VERSION "5.2.0"

NS_ :

BS_:

BU_:

BO_ 2565341438 PGN_59392_isoAcknowledgement: 8 Vector__XXX
 SG_ pgn : 40|24@1+ (1,0) [0|0] "" Vector__XXX
 SG_ reserved : 16|24@1+ (1,0) [0|0] "" Vector__XXX
 SG_ groupFunction : 8|8@1+ (1,0) [0|0] "" Vector__XXX
 SG_ control : 0|8@1+ (1,0) [0|0] "" Vector__XXX

BO_ 2565472510 PGN_59904_isoRequest: 8 Vector__XXX
 SG_ pgn : 0|24@1+ (1,0) [0|0] "" Vector__XXX

BO_ 2565538046 PGN_60160_isoTransportProtocolDa: 8 Vector__XXX
 SG_ data : 8|56@1+ (1,0) [0|0] "" Vector__XXX
 SG_ sid : 0|8@1+ (1,0) [0|0] "" Vector__XXX

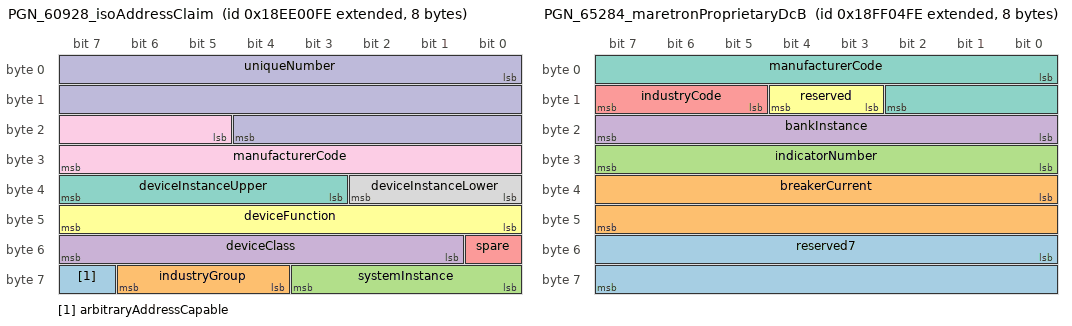
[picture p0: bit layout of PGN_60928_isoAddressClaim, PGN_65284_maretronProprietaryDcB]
BO_ 2565734654 PGN_60928_isoAddressClaim: 8 Vector__XXX
 SG_ arbitraryAddressCapable : 63|1@1+ (1,0) [0|0] "" Vector__XXX
 SG_ industryGroup : 60|3@1+ (1,0) [0|0] "" Vector__XXX
 SG_ systemInstance : 56|4@1+ (1,0) [0|0] "" Vector__XXX
 SG_ deviceClass : 49|7@1+ (1,0) [0|0] "" Vector__XXX
 SG_ spare : 48|1@1+ (1,0) [0|0] "" Vector__XXX
 SG_ deviceFunction : 40|8@1+ (1,0) [0|0] "" Vector__XXX
 SG_ deviceInstanceUpper : 35|5@1+ (1,0) [0|0] "" Vector__XXX
 SG_ deviceInstanceLower : 32|3@1+ (1,0) [0|0] "" Vector__XXX
 SG_ manufacturerCode : 21|11@1+ (1,0) [0|0] "" Vector__XXX
 SG_ uniqueNumber : 0|21@1+ (1,0) [0|0] "" Vector__XXX

BO_ 2566777342 PGN_65001_bus1PhaseCBasicAcQuant: 8 Vector__XXX
 SG_ reserved : 48|16@1+ (1,0) [0|0] "" Vector__XXX
 SG_ acFrequency : 32|16@1+ (0.0078125,0) [0|0] "Hz" Vector__XXX
 SG_ lineNeutralAcRmsVoltage : 16|16@1+ (1,0) [0|0] "V" Vector__XXX
 SG_ lineLineAcRmsVoltage : 0|16@1+ (1,0) [0|0] "V" Vector__XXX

BO_ 2566777598 PGN_65002_bus1PhaseBBasicAcQuant: 8 Vector__XXX
 SG_ reserved : 48|16@1+ (1,0) [0|0] "" Vector__XXX
 SG_ acFrequency : 32|16@1+ (0.0078125,0) [0|0] "Hz" Vector__XXX
 SG_ lineNeutralAcRmsVoltage : 16|16@1+ (1,0) [0|0] "V" Vector__XXX
 SG_ lineLineAcRmsVoltage : 0|16@1+ (1,0) [0|0] "V" Vector__XXX

BO_ 2566777854 PGN_65003_bus1PhaseABasicAcQuant: 8 Vector__XXX
 SG_ reserved : 48|16@1+ (1,0) [0|0] "" Vector__XXX
 SG_ acFrequency : 32|16@1+ (0.0078125,0) [0|0] "Hz" Vector__XXX
 SG_ lineNeutralAcRmsVoltage : 16|16@1+ (1,0) [0|0] "V" Vector__XXX
 SG_ lineLineAcRmsVoltage : 0|16@1+ (1,0) [0|0] "V" Vector__XXX

BO_ 2566778110 PGN_65004_bus1AverageBasicAcQuan: 8 Vector__XXX
 SG_ reserved : 48|16@1+ (1,0) [0|0] "" Vector__XXX
 SG_ acFrequency : 32|16@1+ (0.0078125,0) [0|0] "Hz" Vector__XXX
 SG_ lineNeutralAcRmsVoltage : 16|16@1+ (1,0) [0|0] "V" Vector__XXX
 SG_ lineLineAcRmsVoltage : 0|16@1+ (1,0) [0|0] "V" Vector__XXX

BO_ 2566778366 PGN_65005_utilityTotalAcEnergy: 8 Vector__XXX
 SG_ totalEnergyImport : 32|32@1+ (1,0) [0|0] "kWh" Vector__XXX
 SG_ totalEnergyExport : 0|32@1+ (1,0) [0|0] "kWh" Vector__XXX

BO_ 2566778622 PGN_65006_utilityPhaseCAcReactiv: 8 Vector__XXX
 SG_ reserved : 34|30@1+ (1,0) [0|0] "" Vector__XXX
 SG_ powerFactorLagging : 32|2@1+ (1,0) [0|0] "" Vector__XXX
 SG_ powerFactor : 16|16@1+ (6.10352e-05,0) [0|0] "Cos Phi" Vector__XXX
 SG_ reactivePower : 0|16@1+ (1,0) [0|0] "VAR" Vector__XXX

BO_ 2566778878 PGN_65007_utilityPhaseCAcPower: 8 Vector__XXX
 SG_ apparentPower : 32|32@1- (1,0) [0|0] "VA" Vector__XXX
 SG_ realPower : 0|32@1- (1,0) [0|0] "W" Vector__XXX

BO_ 2566779134 PGN_65008_utilityPhaseCBasicAcQu: 8 Vector__XXX
 SG_ acRmsCurrent : 48|16@1+ (1,0) [0|0] "A" Vector__XXX
 SG_ acFrequency : 32|16@1+ (0.0078125,0) [0|0] "Hz" Vector__XXX
 SG_ lineNeutralAcRmsVoltage : 16|16@1+ (1,0) [0|0] "V" Vector__XXX
 SG_ lineLineAcRmsVoltage : 0|16@1+ (1,0) [0|0] "V" Vector__XXX

BO_ 2566779390 PGN_65009_utilityPhaseBAcReactiv: 8 Vector__XXX
 SG_ reserved : 34|30@1+ (1,0) [0|0] "" Vector__XXX
 SG_ powerFactorLagging : 32|2@1+ (1,0) [0|0] "" Vector__XXX
 SG_ powerFactor : 16|16@1+ (6.10352e-05,0) [0|0] "Cos Phi" Vector__XXX
 SG_ reactivePower : 0|16@1+ (1,0) [0|0] "VAR" Vector__XXX

BO_ 2566779646 PGN_65010_utilityPhaseBAcPower: 8 Vector__XXX
 SG_ apparentPower : 32|32@1- (1,0) [0|0] "VA" Vector__XXX
 SG_ realPower : 0|32@1- (1,0) [0|0] "W" Vector__XXX

BO_ 2566779902 PGN_65011_utilityPhaseBBasicAcQu: 8 Vector__XXX
 SG_ acRmsCurrent : 48|16@1+ (1,0) [0|0] "A" Vector__XXX
 SG_ acFrequency : 32|16@1+ (0.0078125,0) [0|0] "Hz" Vector__XXX
 SG_ lineNeutralAcRmsVoltage : 16|16@1+ (1,0) [0|0] "V" Vector__XXX
 SG_ lineLineAcRmsVoltage : 0|16@1+ (1,0) [0|0] "V" Vector__XXX

BO_ 2566780158 PGN_65012_utilityPhaseAAcReactiv: 8 Vector__XXX
 SG_ reserved : 50|14@1+ (1,0) [0|0] "" Vector__XXX
 SG_ powerFactorLagging : 48|2@1+ (1,0) [0|0] "" Vector__XXX
 SG_ powerFactor : 32|16@1+ (6.10352e-05,0) [0|0] "Cos Phi" Vector__XXX
 SG_ reactivePower : 0|32@1- (1,0) [0|0] "VAR" Vector__XXX

BO_ 2566780414 PGN_65013_utilityPhaseAAcPower: 8 Vector__XXX
 SG_ apparentPower : 32|32@1- (1,0) [0|0] "VA" Vector__XXX
 SG_ realPower : 0|32@1- (1,0) [0|0] "W" Vector__XXX

BO_ 2566780670 PGN_65014_utilityPhaseABasicAcQu: 8 Vector__XXX
 SG_ acRmsCurrent : 48|16@1+ (1,0) [0|0] "A" Vector__XXX
 SG_ acFrequency : 32|16@1+ (0.0078125,0) [0|0] "Hz" Vector__XXX
 SG_ lineNeutralAcRmsVoltage : 16|16@1+ (1,0) [0|0] "V" Vector__XXX
 SG_ lineLineAcRmsVoltage : 0|16@1+ (1,0) [0|0] "V" Vector__XXX

BO_ 2566780926 PGN_65015_utilityTotalAcReactive: 8 Vector__XXX
 SG_ reserved : 50|14@1+ (1,0) [0|0] "" Vector__XXX
 SG_ powerFactorLagging : 48|2@1+ (1,0) [0|0] "" Vector__XXX
 SG_ powerFactor : 32|16@1+ (6.10352e-05,0) [0|0] "Cos Phi" Vector__XXX
 SG_ reactivePower : 0|32@1- (1,0) [0|0] "VAR" Vector__XXX

BO_ 2566781182 PGN_65016_utilityTotalAcPower: 8 Vector__XXX
 SG_ apparentPower : 32|32@1- (1,0) [0|0] "VA" Vector__XXX
 SG_ realPower : 0|32@1- (1,0) [0|0] "W" Vector__XXX

BO_ 2566781438 PGN_65017_utilityAverageBasicAcQ: 8 Vector__XXX
 SG_ acRmsCurrent : 48|16@1+ (1,0) [0|0] "A" Vector__XXX
 SG_ acFrequency : 32|16@1+ (0.0078125,0) [0|0] "Hz" Vector__XXX
 SG_ lineNeutralAcRmsVoltage : 16|16@1+ (1,0) [0|0] "V" Vector__XXX
 SG_ lineLineAcRmsVoltage : 0|16@1+ (1,0) [0|0] "V" Vector__XXX

BO_ 2566781694 PGN_65018_generatorTotalAcEnergy: 8 Vector__XXX
 SG_ totalEnergyImport : 32|32@1+ (1,0) [0|0] "kWh" Vector__XXX
 SG_ totalEnergyExport : 0|32@1+ (1,0) [0|0] "kWh" Vector__XXX

BO_ 2566781950 PGN_65019_generatorPhaseCAcReact: 8 Vector__XXX
 SG_ reserved : 50|14@1+ (1,0) [0|0] "" Vector__XXX
 SG_ powerFactorLagging : 48|2@1+ (1,0) [0|0] "" Vector__XXX
 SG_ powerFactor : 32|16@1+ (6.10352e-05,0) [0|0] "Cos Phi" Vector__XXX
 SG_ reactivePower : 0|32@1- (1,0) [0|0] "VAR" Vector__XXX

BO_ 2566782206 PGN_65020_generatorPhaseCAcPower: 8 Vector__XXX
 SG_ apparentPower : 32|32@1- (1,0) [0|0] "VAR" Vector__XXX
 SG_ realPower : 0|32@1- (1,0) [0|0] "W" Vector__XXX

BO_ 2566782462 PGN_65021_generatorPhaseCBasicAc: 8 Vector__XXX
 SG_ acRmsCurrent : 48|16@1+ (1,0) [0|0] "A" Vector__XXX
 SG_ acFrequency : 32|16@1+ (0.0078125,0) [0|0] "Hz" Vector__XXX
 SG_ lineNeutralAcRmsVoltage : 16|16@1+ (1,0) [0|0] "V" Vector__XXX
 SG_ lineLineAcRmsVoltage : 0|16@1+ (1,0) [0|0] "V" Vector__XXX

BO_ 2566782718 PGN_65022_generatorPhaseBAcReact: 8 Vector__XXX
 SG_ reserved : 50|14@1+ (1,0) [0|0] "" Vector__XXX
 SG_ powerFactorLagging : 48|2@1+ (1,0) [0|0] "" Vector__XXX
 SG_ powerFactor : 32|16@1+ (6.10352e-05,0) [0|0] "Cos Phi" Vector__XXX
 SG_ reactivePower : 0|32@1- (1,0) [0|0] "VAR" Vector__XXX

BO_ 2566782974 PGN_65023_generatorPhaseBAcPower: 8 Vector__XXX
 SG_ apparentPower : 32|32@1- (1,0) [0|0] "VA" Vector__XXX
 SG_ realPower : 0|32@1- (1,0) [0|0] "W" Vector__XXX

BO_ 2566783230 PGN_65024_generatorPhaseBBasicAc: 8 Vector__XXX
 SG_ acRmsCurrent : 48|16@1+ (1,0) [0|0] "A" Vector__XXX
 SG_ acFrequency : 32|16@1+ (0.0078125,0) [0|0] "Hz" Vector__XXX
 SG_ lineNeutralAcRmsVoltage : 16|16@1+ (1,0) [0|0] "V" Vector__XXX
 SG_ lineLineAcRmsVoltage : 0|16@1+ (1,0) [0|0] "V" Vector__XXX

BO_ 2566783486 PGN_65025_generatorPhaseAAcReact: 8 Vector__XXX
 SG_ reserved : 50|14@1+ (1,0) [0|0] "" Vector__XXX
 SG_ powerFactorLagging : 48|2@1+ (1,0) [0|0] "" Vector__XXX
 SG_ powerFactor : 32|16@1+ (6.10352e-05,0) [0|0] "Cos Phi" Vector__XXX
 SG_ reactivePower : 0|32@1- (1,0) [0|0] "VAR" Vector__XXX

BO_ 2566783742 PGN_65026_generatorPhaseAAcPower: 8 Vector__XXX
 SG_ apparentPower : 32|32@1- (1,0) [0|0] "VA" Vector__XXX
 SG_ realPower : 0|32@1- (1,0) [0|0] "W" Vector__XXX

BO_ 2566783998 PGN_65027_generatorPhaseABasicAc: 8 Vector__XXX
 SG_ acRmsCurrent : 48|16@1+ (1,0) [0|0] "A" Vector__XXX
 SG_ acFrequency : 32|16@1+ (0.0078125,0) [0|0] "Hz" Vector__XXX
 SG_ lineNeutralAcRmsVoltage : 16|16@1+ (1,0) [0|0] "V" Vector__XXX
 SG_ lineLineAcRmsVoltage : 0|16@1+ (1,0) [0|0] "V" Vector__XXX

BO_ 2566784254 PGN_65028_generatorTotalAcReacti: 8 Vector__XXX
 SG_ reserved : 50|14@1+ (1,0) [0|0] "" Vector__XXX
 SG_ powerFactorLagging : 48|2@1+ (1,0) [0|0] "" Vector__XXX
 SG_ powerFactor : 32|16@1+ (6.10352e-05,0) [0|0] "Cos Phi" Vector__XXX
 SG_ reactivePower : 0|32@1- (1,0) [0|0] "VAR" Vector__XXX

BO_ 2566784510 PGN_65029_generatorTotalAcPower: 8 Vector__XXX
 SG_ apparentPower : 32|32@1- (1,0) [0|0] "VA" Vector__XXX
 SG_ realPower : 0|32@1- (1,0) [0|0] "W" Vector__XXX

BO_ 2566784766 PGN_65030_generatorAverageBasicA: 8 Vector__XXX
 SG_ acRmsCurrent : 48|16@1+ (1,0) [0|0] "A" Vector__XXX
 SG_ acFrequency : 32|16@1+ (0.0078125,0) [0|0] "Hz" Vector__XXX
 SG_ lineNeutralAcRmsVoltage : 16|16@1+ (1,0) [0|0] "V" Vector__XXX
 SG_ lineLineAcRmsVoltage : 0|16@1+ (1,0) [0|0] "V" Vector__XXX

BO_ 2566848766 PGN_65280_furunoHeave: 8 Vector__XXX
 SG_ reserved5 : 48|16@1+ (1,0) [0|0] "" Vector__XXX
 SG_ heave : 16|32@1- (0.001,0) [0|0] "m" Vector__XXX
 SG_ industryCode : 13|3@1+ (1,0) [0|0] "" Vector__XXX
 SG_ reserved : 11|2@1+ (1,0) [0|0] "" Vector__XXX
 SG_ manufacturerCode : 0|11@1+ (1,0) [0|0] "" Vector__XXX

BO_ 2566849790 PGN_65284_maretronProprietaryDcB: 8 Vector__XXX
 SG_ reserved7 : 48|16@1+ (1,0) [0|0] "" Vector__XXX
 SG_ breakerCurrent : 32|16@1+ (0.1,0) [0|0] "A" Vector__XXX
 SG_ indicatorNumber : 24|8@1+ (1,0) [0|0] "" Vector__XXX
 SG_ bankInstance : 16|8@1+ (1,0) [0|0] "" Vector__XXX
 SG_ industryCode : 13|3@1+ (1,0) [0|0] "" Vector__XXX
 SG_ reserved : 11|2@1+ (1,0) [0|0] "" Vector__XXX
 SG_ manufacturerCode : 0|11@1+ (1,0) [0|0] "" Vector__XXX

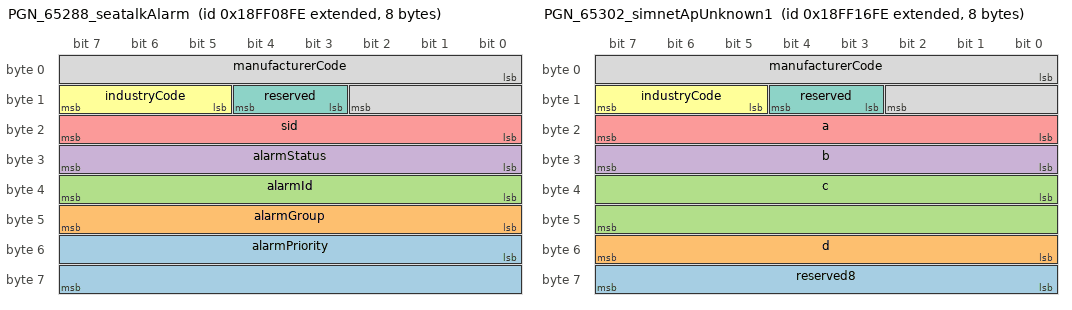
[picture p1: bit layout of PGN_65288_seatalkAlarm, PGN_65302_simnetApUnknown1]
BO_ 2566850814 PGN_65288_seatalkAlarm: 8 Vector__XXX
 SG_ alarmPriority : 48|16@1+ (1,0) [0|0] "" Vector__XXX
 SG_ alarmGroup : 40|8@1+ (1,0) [0|0] "" Vector__XXX
 SG_ alarmId : 32|8@1+ (1,0) [0|0] "" Vector__XXX
 SG_ alarmStatus : 24|8@1+ (1,0) [0|0] "" Vector__XXX
 SG_ sid : 16|8@1+ (1,0) [0|0] "" Vector__XXX
 SG_ industryCode : 13|3@1+ (1,0) [0|0] "" Vector__XXX
 SG_ reserved : 11|2@1+ (1,0) [0|0] "" Vector__XXX
 SG_ manufacturerCode : 0|11@1+ (1,0) [0|0] "" Vector__XXX

BO_ 2566851070 PGN_65289_simnetTrimTabSensorCal: 8 Vector__XXX
 SG_ reserved4 : 16|48@1+ (1,0) [0|0] "" Vector__XXX
 SG_ industryCode : 13|3@1+ (1,0) [0|0] "" Vector__XXX
 SG_ reserved : 11|2@1+ (1,0) [0|0] "" Vector__XXX
 SG_ manufacturerCode : 0|11@1+ (1,0) [0|0] "" Vector__XXX

BO_ 2566851326 PGN_65290_simnetPaddleWheelSpeed: 8 Vector__XXX
 SG_ reserved4 : 16|48@1+ (1,0) [0|0] "" Vector__XXX
 SG_ industryCode : 13|3@1+ (1,0) [0|0] "" Vector__XXX
 SG_ reserved : 11|2@1+ (1,0) [0|0] "" Vector__XXX
 SG_ manufacturerCode : 0|11@1+ (1,0) [0|0] "" Vector__XXX

BO_ 2566851838 PGN_65292_simnetClearFluidLevelW: 8 Vector__XXX
 SG_ reserved4 : 16|48@1+ (1,0) [0|0] "" Vector__XXX
 SG_ industryCode : 13|3@1+ (1,0) [0|0] "" Vector__XXX
 SG_ reserved : 11|2@1+ (1,0) [0|0] "" Vector__XXX
 SG_ manufacturerCode : 0|11@1+ (1,0) [0|0] "" Vector__XXX

BO_ 2566854398 PGN_65302_simnetApUnknown1: 8 Vector__XXX
 SG_ reserved8 : 56|8@1+ (1,0) [0|0] "" Vector__XXX
 SG_ d : 48|8@1+ (1,0) [0|0] "" Vector__XXX
 SG_ c : 32|16@1+ (1,0) [0|0] "" Vector__XXX
 SG_ b : 24|8@1+ (1,0) [0|0] "" Vector__XXX
 SG_ a : 16|8@1+ (1,0) [0|0] "" Vector__XXX
 SG_ industryCode : 13|3@1+ (1,0) [0|0] "" Vector__XXX
 SG_ reserved : 11|2@1+ (1,0) [0|0] "" Vector__XXX
 SG_ manufacturerCode : 0|11@1+ (1,0) [0|0] "" Vector__XXX

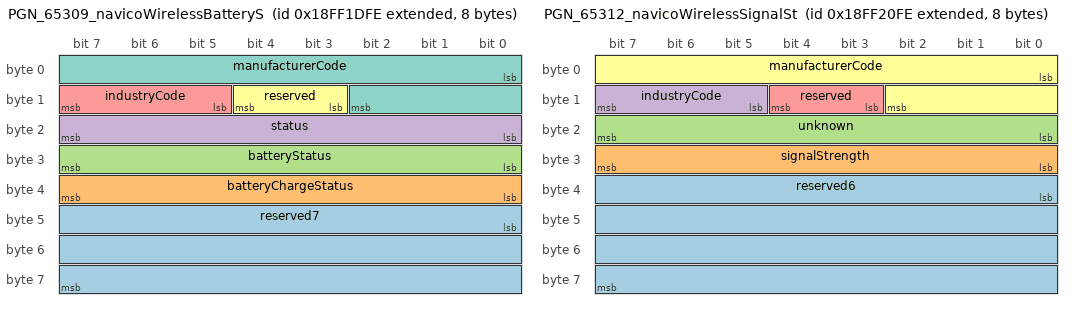
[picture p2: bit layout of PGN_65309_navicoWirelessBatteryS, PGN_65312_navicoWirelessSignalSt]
BO_ 2566856190 PGN_65309_navicoWirelessBatteryS: 8 Vector__XXX
 SG_ reserved7 : 40|24@1+ (1,0) [0|0] "" Vector__XXX
 SG_ batteryChargeStatus : 32|8@1+ (1,0) [0|0] "%" Vector__XXX
 SG_ batteryStatus : 24|8@1+ (1,0) [0|0] "%" Vector__XXX
 SG_ status : 16|8@1+ (1,0) [0|0] "" Vector__XXX
 SG_ industryCode : 13|3@1+ (1,0) [0|0] "" Vector__XXX
 SG_ reserved : 11|2@1+ (1,0) [0|0] "" Vector__XXX
 SG_ manufacturerCode : 0|11@1+ (1,0) [0|0] "" Vector__XXX

BO_ 2566856958 PGN_65312_navicoWirelessSignalSt: 8 Vector__XXX
 SG_ reserved6 : 32|32@1+ (1,0) [0|0] "" Vector__XXX
 SG_ signalStrength : 24|8@1+ (1,0) [0|0] "%" Vector__XXX
 SG_ unknown : 16|8@1+ (1,0) [0|0] "" Vector__XXX
 SG_ industryCode : 13|3@1+ (1,0) [0|0] "" Vector__XXX
 SG_ reserved : 11|2@1+ (1,0) [0|0] "" Vector__XXX
 SG_ manufacturerCode : 0|11@1+ (1,0) [0|0] "" Vector__XXX

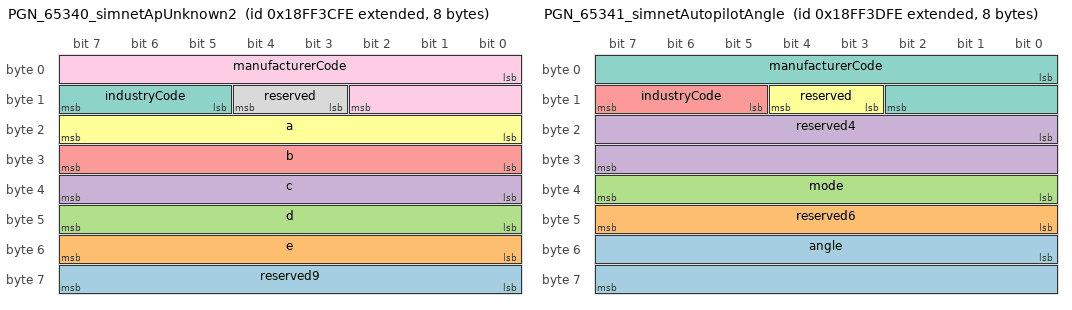
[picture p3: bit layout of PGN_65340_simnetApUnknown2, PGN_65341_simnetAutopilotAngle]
BO_ 2566864126 PGN_65340_simnetApUnknown2: 8 Vector__XXX
 SG_ reserved9 : 56|8@1+ (1,0) [0|0] "" Vector__XXX
 SG_ e : 48|8@1+ (1,0) [0|0] "" Vector__XXX
 SG_ d : 40|8@1+ (1,0) [0|0] "" Vector__XXX
 SG_ c : 32|8@1+ (1,0) [0|0] "" Vector__XXX
 SG_ b : 24|8@1+ (1,0) [0|0] "" Vector__XXX
 SG_ a : 16|8@1+ (1,0) [0|0] "" Vector__XXX
 SG_ industryCode : 13|3@1+ (1,0) [0|0] "" Vector__XXX
 SG_ reserved : 11|2@1+ (1,0) [0|0] "" Vector__XXX
 SG_ manufacturerCode : 0|11@1+ (1,0) [0|0] "" Vector__XXX

BO_ 2566864382 PGN_65341_simnetAutopilotAngle: 8 Vector__XXX
 SG_ angle : 48|16@1+ (0.0001,0) [0|0] "rad" Vector__XXX
 SG_ reserved6 : 40|8@1+ (1,0) [0|0] "" Vector__XXX
 SG_ mode : 32|8@1+ (1,0) [0|0] "" Vector__XXX
 SG_ reserved4 : 16|16@1+ (1,0) [0|0] "" Vector__XXX
 SG_ industryCode : 13|3@1+ (1,0) [0|0] "" Vector__XXX
 SG_ reserved : 11|2@1+ (1,0) [0|0] "" Vector__XXX
 SG_ manufacturerCode : 0|11@1+ (1,0) [0|0] "" Vector__XXX

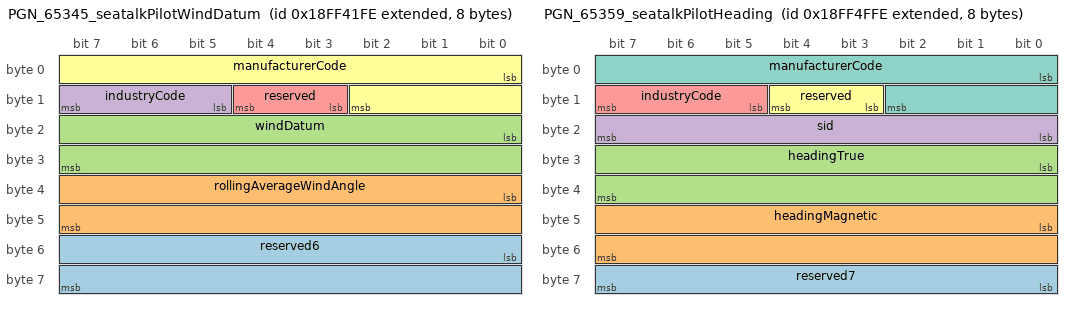
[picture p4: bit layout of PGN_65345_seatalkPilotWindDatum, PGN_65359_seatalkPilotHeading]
BO_ 2566865406 PGN_65345_seatalkPilotWindDatum: 8 Vector__XXX
 SG_ reserved6 : 48|16@1+ (1,0) [0|0] "" Vector__XXX
 SG_ rollingAverageWindAngle : 32|16@1+ (0.0001,0) [0|0] "rad" Vector__XXX
 SG_ windDatum : 16|16@1+ (0.0001,0) [0|0] "rad" Vector__XXX
 SG_ industryCode : 13|3@1+ (1,0) [0|0] "" Vector__XXX
 SG_ reserved : 11|2@1+ (1,0) [0|0] "" Vector__XXX
 SG_ manufacturerCode : 0|11@1+ (1,0) [0|0] "" Vector__XXX

BO_ 2566866686 PGN_65350_simnetMagneticField: 8 Vector__XXX
 SG_ reserved : 56|8@1+ (1,0) [0|0] "" Vector__XXX
 SG_ d : 40|16@1- (0.0001,0) [0|0] "rad" Vector__XXX
 SG_ c : 24|16@1- (0.0001,0) [0|0] "rad" Vector__XXX
 SG_ b : 16|8@1+ (1,0) [0|0] "%" Vector__XXX
 SG_ a : 0|16@1- (0.0001,0) [0|0] "rad" Vector__XXX

BO_ 2566868990 PGN_65359_seatalkPilotHeading: 8 Vector__XXX
 SG_ reserved7 : 56|8@1+ (1,0) [0|0] "" Vector__XXX
 SG_ headingMagnetic : 40|16@1+ (0.0001,0) [0|0] "rad" Vector__XXX
 SG_ headingTrue : 24|16@1+ (0.0001,0) [0|0] "rad" Vector__XXX
 SG_ sid : 16|8@1+ (1,0) [0|0] "" Vector__XXX
 SG_ industryCode : 13|3@1+ (1,0) [0|0] "" Vector__XXX
 SG_ reserved : 11|2@1+ (1,0) [0|0] "" Vector__XXX
 SG_ manufacturerCode : 0|11@1+ (1,0) [0|0] "" Vector__XXX

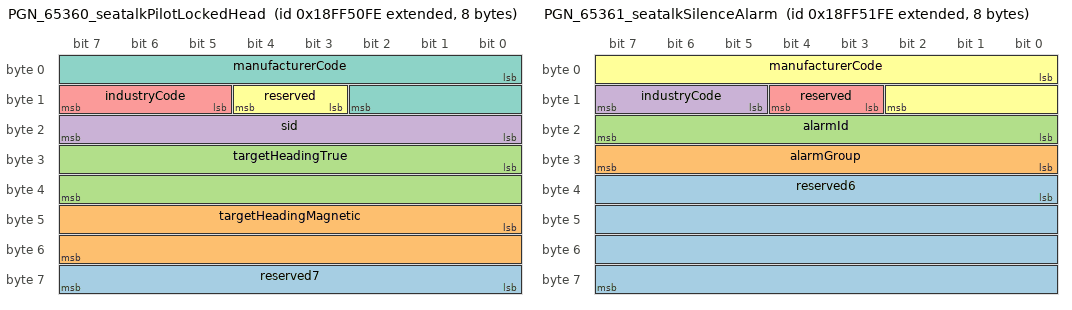
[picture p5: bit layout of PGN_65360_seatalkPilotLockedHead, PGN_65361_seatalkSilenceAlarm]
BO_ 2566869246 PGN_65360_seatalkPilotLockedHead: 8 Vector__XXX
 SG_ reserved7 : 56|8@1+ (1,0) [0|0] "" Vector__XXX
 SG_ targetHeadingMagnetic : 40|16@1+ (0.0001,0) [0|0] "rad" Vector__XXX
 SG_ targetHeadingTrue : 24|16@1+ (0.0001,0) [0|0] "rad" Vector__XXX
 SG_ sid : 16|8@1+ (1,0) [0|0] "" Vector__XXX
 SG_ industryCode : 13|3@1+ (1,0) [0|0] "" Vector__XXX
 SG_ reserved : 11|2@1+ (1,0) [0|0] "" Vector__XXX
 SG_ manufacturerCode : 0|11@1+ (1,0) [0|0] "" Vector__XXX

BO_ 2566869502 PGN_65361_seatalkSilenceAlarm: 8 Vector__XXX
 SG_ reserved6 : 32|32@1+ (1,0) [0|0] "" Vector__XXX
 SG_ alarmGroup : 24|8@1+ (1,0) [0|0] "" Vector__XXX
 SG_ alarmId : 16|8@1+ (1,0) [0|0] "" Vector__XXX
 SG_ industryCode : 13|3@1+ (1,0) [0|0] "" Vector__XXX
 SG_ reserved : 11|2@1+ (1,0) [0|0] "" Vector__XXX
 SG_ manufacturerCode : 0|11@1+ (1,0) [0|0] "" Vector__XXX

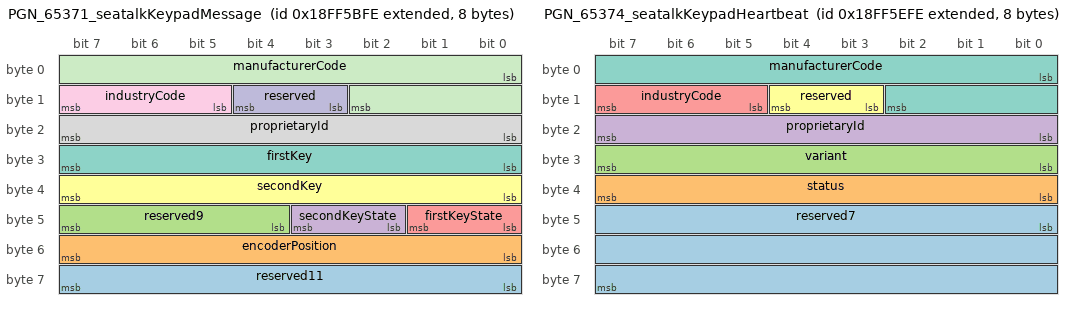
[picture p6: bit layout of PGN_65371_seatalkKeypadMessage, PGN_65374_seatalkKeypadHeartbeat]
BO_ 2566872062 PGN_65371_seatalkKeypadMessage: 8 Vector__XXX
 SG_ reserved11 : 56|8@1+ (1,0) [0|0] "" Vector__XXX
 SG_ encoderPosition : 48|8@1+ (1,0) [0|0] "" Vector__XXX
 SG_ reserved9 : 44|4@1+ (1,0) [0|0] "" Vector__XXX
 SG_ secondKeyState : 42|2@1+ (1,0) [0|0] "" Vector__XXX
 SG_ firstKeyState : 40|2@1+ (1,0) [0|0] "" Vector__XXX
 SG_ secondKey : 32|8@1+ (1,0) [0|0] "" Vector__XXX
 SG_ firstKey : 24|8@1+ (1,0) [0|0] "" Vector__XXX
 SG_ proprietaryId : 16|8@1+ (1,0) [0|0] "" Vector__XXX
 SG_ industryCode : 13|3@1+ (1,0) [0|0] "" Vector__XXX
 SG_ reserved : 11|2@1+ (1,0) [0|0] "" Vector__XXX
 SG_ manufacturerCode : 0|11@1+ (1,0) [0|0] "" Vector__XXX

BO_ 2566872830 PGN_65374_seatalkKeypadHeartbeat: 8 Vector__XXX
 SG_ reserved7 : 40|24@1+ (1,0) [0|0] "" Vector__XXX
 SG_ status : 32|8@1+ (1,0) [0|0] "" Vector__XXX
 SG_ variant : 24|8@1+ (1,0) [0|0] "" Vector__XXX
 SG_ proprietaryId : 16|8@1+ (1,0) [0|0] "" Vector__XXX
 SG_ industryCode : 13|3@1+ (1,0) [0|0] "" Vector__XXX
 SG_ reserved : 11|2@1+ (1,0) [0|0] "" Vector__XXX
 SG_ manufacturerCode : 0|11@1+ (1,0) [0|0] "" Vector__XXX

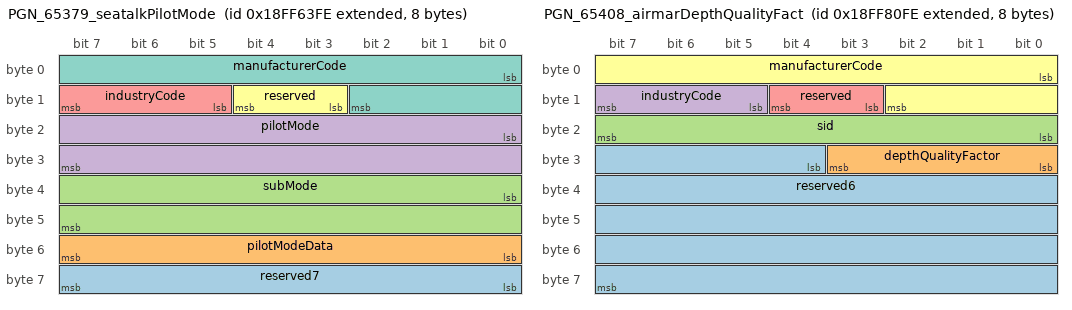
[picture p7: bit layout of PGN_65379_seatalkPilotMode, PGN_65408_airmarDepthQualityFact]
BO_ 2566874110 PGN_65379_seatalkPilotMode: 8 Vector__XXX
 SG_ reserved7 : 56|8@1+ (1,0) [0|0] "" Vector__XXX
 SG_ pilotModeData : 48|8@1+ (1,0) [0|0] "" Vector__XXX
 SG_ subMode : 32|16@1+ (1,0) [0|0] "" Vector__XXX
 SG_ pilotMode : 16|16@1+ (1,0) [0|0] "" Vector__XXX
 SG_ industryCode : 13|3@1+ (1,0) [0|0] "" Vector__XXX
 SG_ reserved : 11|2@1+ (1,0) [0|0] "" Vector__XXX
 SG_ manufacturerCode : 0|11@1+ (1,0) [0|0] "" Vector__XXX

BO_ 2566881534 PGN_65408_airmarDepthQualityFact: 8 Vector__XXX
 SG_ reserved6 : 28|36@1+ (1,0) [0|0] "" Vector__XXX
 SG_ depthQualityFactor : 24|4@1+ (1,0) [0|0] "" Vector__XXX
 SG_ sid : 16|8@1+ (1,0) [0|0] "" Vector__XXX
 SG_ industryCode : 13|3@1+ (1,0) [0|0] "" Vector__XXX
 SG_ reserved : 11|2@1+ (1,0) [0|0] "" Vector__XXX
 SG_ manufacturerCode : 0|11@1+ (1,0) [0|0] "" Vector__XXX

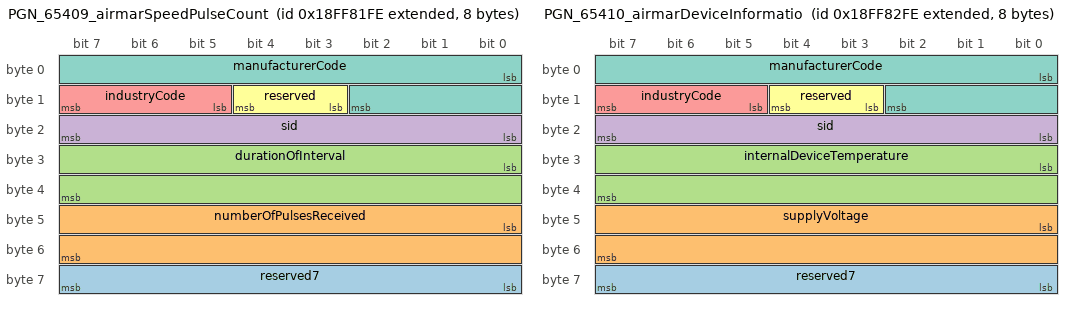
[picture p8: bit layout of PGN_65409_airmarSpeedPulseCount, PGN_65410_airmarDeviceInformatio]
BO_ 2566881790 PGN_65409_airmarSpeedPulseCount: 8 Vector__XXX
 SG_ reserved7 : 56|8@1+ (1,0) [0|0] "" Vector__XXX
 SG_ numberOfPulsesReceived : 40|16@1+ (1,0) [0|0] "" Vector__XXX
 SG_ durationOfInterval : 24|16@1+ (0.001,0) [0|0] "s" Vector__XXX
 SG_ sid : 16|8@1+ (1,0) [0|0] "" Vector__XXX
 SG_ industryCode : 13|3@1+ (1,0) [0|0] "" Vector__XXX
 SG_ reserved : 11|2@1+ (1,0) [0|0] "" Vector__XXX
 SG_ manufacturerCode : 0|11@1+ (1,0) [0|0] "" Vector__XXX

BO_ 2566882046 PGN_65410_airmarDeviceInformatio: 8 Vector__XXX
 SG_ reserved7 : 56|8@1+ (1,0) [0|0] "" Vector__XXX
 SG_ supplyVoltage : 40|16@1+ (0.01,0) [0|0] "V" Vector__XXX
 SG_ internalDeviceTemperature : 24|16@1+ (0.01,0) [0|0] "K" Vector__XXX
 SG_ sid : 16|8@1+ (1,0) [0|0] "" Vector__XXX
 SG_ industryCode : 13|3@1+ (1,0) [0|0] "" Vector__XXX
 SG_ reserved : 11|2@1+ (1,0) [0|0] "" Vector__XXX
 SG_ manufacturerCode : 0|11@1+ (1,0) [0|0] "" Vector__XXX

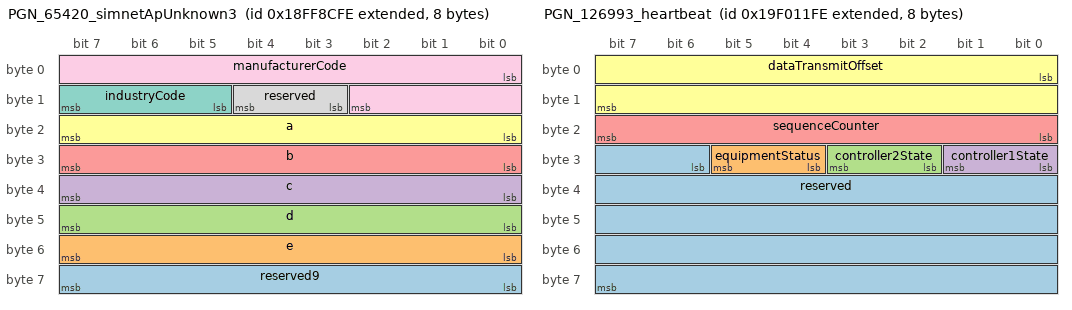
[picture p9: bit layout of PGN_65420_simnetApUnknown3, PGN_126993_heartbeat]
BO_ 2566884606 PGN_65420_simnetApUnknown3: 8 Vector__XXX
 SG_ reserved9 : 56|8@1+ (1,0) [0|0] "" Vector__XXX
 SG_ e : 48|8@1+ (1,0) [0|0] "" Vector__XXX
 SG_ d : 40|8@1+ (1,0) [0|0] "" Vector__XXX
 SG_ c : 32|8@1+ (1,0) [0|0] "" Vector__XXX
 SG_ b : 24|8@1+ (1,0) [0|0] "" Vector__XXX
 SG_ a : 16|8@1+ (1,0) [0|0] "" Vector__XXX
 SG_ industryCode : 13|3@1+ (1,0) [0|0] "" Vector__XXX
 SG_ reserved : 11|2@1+ (1,0) [0|0] "" Vector__XXX
 SG_ manufacturerCode : 0|11@1+ (1,0) [0|0] "" Vector__XXX

BO_ 2566899966 PGN_65480_simnetAutopilotMode: 8 Vector__XXX
 SG_ reserved4 : 16|48@1+ (1,0) [0|0] "" Vector__XXX
 SG_ industryCode : 13|3@1+ (1,0) [0|0] "" Vector__XXX
 SG_ reserved : 11|2@1+ (1,0) [0|0] "" Vector__XXX
 SG_ manufacturerCode : 0|11@1+ (1,0) [0|0] "" Vector__XXX

BO_ 2582511870 PGN_126464_pgnListTransmitAndRec: 8 Vector__XXX
 SG_ fastPacketData : 8|56@1+ (1,0) [0|0] "" Vector__XXX
 SG_ fastPacketSequenceCounter : 0|8@1+ (1,0) [0|0] "" Vector__XXX

BO_ 2582644734 PGN_126983_alert: 8 Vector__XXX
 SG_ fastPacketData : 8|56@1+ (1,0) [0|0] "" Vector__XXX
 SG_ fastPacketSequenceCounter : 0|8@1+ (1,0) [0|0] "" Vector__XXX

BO_ 2582644990 PGN_126984_alertResponse: 8 Vector__XXX
 SG_ fastPacketData : 8|56@1+ (1,0) [0|0] "" Vector__XXX
 SG_ fastPacketSequenceCounter : 0|8@1+ (1,0) [0|0] "" Vector__XXX

BO_ 2582645246 PGN_126985_alertText: 8 Vector__XXX
 SG_ fastPacketData : 8|56@1+ (1,0) [0|0] "" Vector__XXX
 SG_ fastPacketSequenceCounter : 0|8@1+ (1,0) [0|0] "" Vector__XXX

BO_ 2582645502 PGN_126986_alertConfiguration: 8 Vector__XXX
 SG_ fastPacketData : 8|56@1+ (1,0) [0|0] "" Vector__XXX
 SG_ fastPacketSequenceCounter : 0|8@1+ (1,0) [0|0] "" Vector__XXX

BO_ 2582645758 PGN_126987_alertThreshold: 8 Vector__XXX
 SG_ fastPacketData : 8|56@1+ (1,0) [0|0] "" Vector__XXX
 SG_ fastPacketSequenceCounter : 0|8@1+ (1,0) [0|0] "" Vector__XXX

BO_ 2582646014 PGN_126988_alertValue: 8 Vector__XXX
 SG_ fastPacketData : 8|56@1+ (1,0) [0|0] "" Vector__XXX
 SG_ fastPacketSequenceCounter : 0|8@1+ (1,0) [0|0] "" Vector__XXX

BO_ 2582647038 PGN_126992_systemTime: 8 Vector__XXX
 SG_ time : 32|32@1+ (0.0001,0) [0|0] "s" Vector__XXX
 SG_ date : 16|16@1+ (1,0) [0|0] "d" Vector__XXX
 SG_ reserved : 12|4@1+ (1,0) [0|0] "" Vector__XXX
 SG_ source : 8|4@1+ (1,0) [0|0] "" Vector__XXX
 SG_ sid : 0|8@1+ (1,0) [0|0] "" Vector__XXX

BO_ 2582647294 PGN_126993_heartbeat: 8 Vector__XXX
 SG_ reserved : 30|34@1+ (1,0) [0|0] "" Vector__XXX
 SG_ equipmentStatus : 28|2@1+ (1,0) [0|0] "" Vector__XXX
 SG_ controller2State : 26|2@1+ (1,0) [0|0] "" Vector__XXX
 SG_ controller1State : 24|2@1+ (1,0) [0|0] "" Vector__XXX
 SG_ sequenceCounter : 16|8@1+ (1,0) [0|0] "" Vector__XXX
 SG_ dataTransmitOffset : 0|16@1+ (0.01,0) [0|0] "s" Vector__XXX

BO_ 2582648062 PGN_126996_productInformation: 8 Vector__XXX
 SG_ fastPacketData : 8|56@1+ (1,0) [0|0] "" Vector__XXX
 SG_ fastPacketSequenceCounter : 0|8@1+ (1,0) [0|0] "" Vector__XXX

BO_ 2582648574 PGN_126998_configurationInformat: 8 Vector__XXX
 SG_ fastPacketData : 8|56@1+ (1,0) [0|0] "" Vector__XXX
 SG_ fastPacketSequenceCounter : 0|8@1+ (1,0) [0|0] "" Vector__XXX

BO_ 2582708734 PGN_127233_manOverboardNotificat: 8 Vector__XXX
 SG_ fastPacketData : 8|56@1+ (1,0) [0|0] "" Vector__XXX
 SG_ fastPacketSequenceCounter : 0|8@1+ (1,0) [0|0] "" Vector__XXX

BO_ 2582709758 PGN_127237_headingTrackControl: 8 Vector__XXX
 SG_ fastPacketData : 8|56@1+ (1,0) [0|0] "" Vector__XXX
 SG_ fastPacketSequenceCounter : 0|8@1+ (1,0) [0|0] "" Vector__XXX

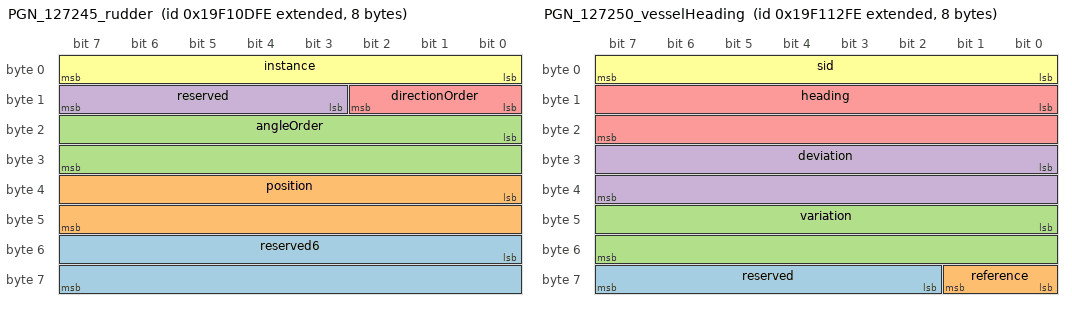
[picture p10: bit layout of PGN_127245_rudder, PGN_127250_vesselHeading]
BO_ 2582711806 PGN_127245_rudder: 8 Vector__XXX
 SG_ reserved6 : 48|16@1+ (1,0) [0|0] "" Vector__XXX
 SG_ position : 32|16@1- (0.0001,0) [0|0] "rad" Vector__XXX
 SG_ angleOrder : 16|16@1- (0.0001,0) [0|0] "rad" Vector__XXX
 SG_ reserved : 11|5@1+ (1,0) [0|0] "" Vector__XXX
 SG_ directionOrder : 8|3@1+ (1,0) [0|0] "" Vector__XXX
 SG_ instance : 0|8@1+ (1,0) [0|0] "" Vector__XXX

BO_ 2582713086 PGN_127250_vesselHeading: 8 Vector__XXX
 SG_ reserved : 58|6@1+ (1,0) [0|0] "" Vector__XXX
 SG_ reference : 56|2@1+ (1,0) [0|0] "" Vector__XXX
 SG_ variation : 40|16@1- (0.0001,0) [0|0] "rad" Vector__XXX
 SG_ deviation : 24|16@1- (0.0001,0) [0|0] "rad" Vector__XXX
 SG_ heading : 8|16@1+ (0.0001,0) [0|0] "rad" Vector__XXX
 SG_ sid : 0|8@1+ (1,0) [0|0] "" Vector__XXX

BO_ 2582713342 PGN_127251_rateOfTurn: 8 Vector__XXX
 SG_ reserved : 40|24@1+ (1,0) [0|0] "" Vector__XXX
 SG_ someRate : 8|32@1- (3.125e-08,0) [0|0] "rad/s" Vector__XXX
 SG_ someSID : 0|8@1+ (1,0) [0|0] "" Vector__XXX

BO_ 2582713598 PGN_127252_heave: 8 Vector__XXX
 SG_ reserved : 24|40@1+ (1,0) [0|0] "" Vector__XXX
 SG_ heave : 8|16@1- (0.01,0) [0|0] "m" Vector__XXX
 SG_ sid : 0|8@1+ (1,0) [0|0] "" Vector__XXX

BO_ 2582714878 PGN_127257_attitude: 8 Vector__XXX
 SG_ reserved : 56|8@1+ (1,0) [0|0] "" Vector__XXX
 SG_ roll : 40|16@1- (0.0001,0) [0|0] "rad" Vector__XXX
 SG_ pitch : 24|16@1- (0.0001,0) [0|0] "rad" Vector__XXX
 SG_ yaw : 8|16@1- (0.0001,0) [0|0] "rad" Vector__XXX
 SG_ sid : 0|8@1+ (1,0) [0|0] "" Vector__XXX

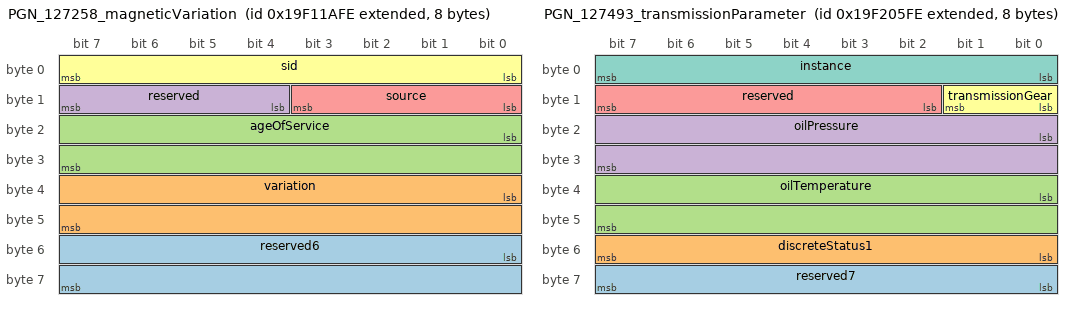
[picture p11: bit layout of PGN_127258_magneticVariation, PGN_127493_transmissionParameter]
BO_ 2582715134 PGN_127258_magneticVariation: 8 Vector__XXX
 SG_ reserved6 : 48|16@1+ (1,0) [0|0] "" Vector__XXX
 SG_ variation : 32|16@1- (0.0001,0) [0|0] "rad" Vector__XXX
 SG_ ageOfService : 16|16@1+ (1,0) [0|0] "d" Vector__XXX
 SG_ reserved : 12|4@1+ (1,0) [0|0] "" Vector__XXX
 SG_ source : 8|4@1+ (1,0) [0|0] "" Vector__XXX
 SG_ sid : 0|8@1+ (1,0) [0|0] "" Vector__XXX

BO_ 2582774014 PGN_127488_engineParametersRapid: 8 Vector__XXX
 SG_ reserved : 48|16@1+ (1,0) [0|0] "" Vector__XXX
 SG_ tiltTrim : 40|8@1- (1,0) [0|0] "%" Vector__XXX
 SG_ boostPressure : 24|16@1+ (100,0) [0|0] "Pa" Vector__XXX
 SG_ speed : 8|16@1+ (0.25,0) [0|0] "rpm" Vector__XXX
 SG_ instance : 0|8@1+ (1,0) [0|0] "" Vector__XXX

BO_ 2582774270 PGN_127489_engineParametersDynam: 8 Vector__XXX
 SG_ fastPacketData : 8|56@1+ (1,0) [0|0] "" Vector__XXX
 SG_ fastPacketSequenceCounter : 0|8@1+ (1,0) [0|0] "" Vector__XXX

BO_ 2582774526 PGN_127490_electricDriveStatusDy: 8 Vector__XXX
 SG_ fastPacketData : 8|56@1+ (1,0) [0|0] "" Vector__XXX
 SG_ fastPacketSequenceCounter : 0|8@1+ (1,0) [0|0] "" Vector__XXX

BO_ 2582774782 PGN_127491_electricEnergyStorage: 8 Vector__XXX
 SG_ fastPacketData : 8|56@1+ (1,0) [0|0] "" Vector__XXX
 SG_ fastPacketSequenceCounter : 0|8@1+ (1,0) [0|0] "" Vector__XXX

BO_ 2582775294 PGN_127493_transmissionParameter: 8 Vector__XXX
 SG_ reserved7 : 56|8@1+ (1,0) [0|0] "" Vector__XXX
 SG_ discreteStatus1 : 48|8@1+ (1,0) [0|0] "" Vector__XXX
 SG_ oilTemperature : 32|16@1+ (0.1,0) [0|0] "K" Vector__XXX
 SG_ oilPressure : 16|16@1+ (100,0) [0|0] "Pa" Vector__XXX
 SG_ reserved : 10|6@1+ (1,0) [0|0] "" Vector__XXX
 SG_ transmissionGear : 8|2@1+ (1,0) [0|0] "" Vector__XXX
 SG_ instance : 0|8@1+ (1,0) [0|0] "" Vector__XXX

BO_ 2582775550 PGN_127494_electricDriveInformat: 8 Vector__XXX
 SG_ fastPacketData : 8|56@1+ (1,0) [0|0] "" Vector__XXX
 SG_ fastPacketSequenceCounter : 0|8@1+ (1,0) [0|0] "" Vector__XXX

BO_ 2582775806 PGN_127495_electricEnergyStorage: 8 Vector__XXX
 SG_ fastPacketData : 8|56@1+ (1,0) [0|0] "" Vector__XXX
 SG_ fastPacketSequenceCounter : 0|8@1+ (1,0) [0|0] "" Vector__XXX

BO_ 2582776062 PGN_127496_tripParametersVessel: 8 Vector__XXX
 SG_ fastPacketData : 8|56@1+ (1,0) [0|0] "" Vector__XXX
 SG_ fastPacketSequenceCounter : 0|8@1+ (1,0) [0|0] "" Vector__XXX

BO_ 2582776318 PGN_127497_tripParametersEngine: 8 Vector__XXX
 SG_ fastPacketData : 8|56@1+ (1,0) [0|0] "" Vector__XXX
 SG_ fastPacketSequenceCounter : 0|8@1+ (1,0) [0|0] "" Vector__XXX

BO_ 2582776574 PGN_127498_engineParametersStati: 8 Vector__XXX
 SG_ fastPacketData : 8|56@1+ (1,0) [0|0] "" Vector__XXX
 SG_ fastPacketSequenceCounter : 0|8@1+ (1,0) [0|0] "" Vector__XXX

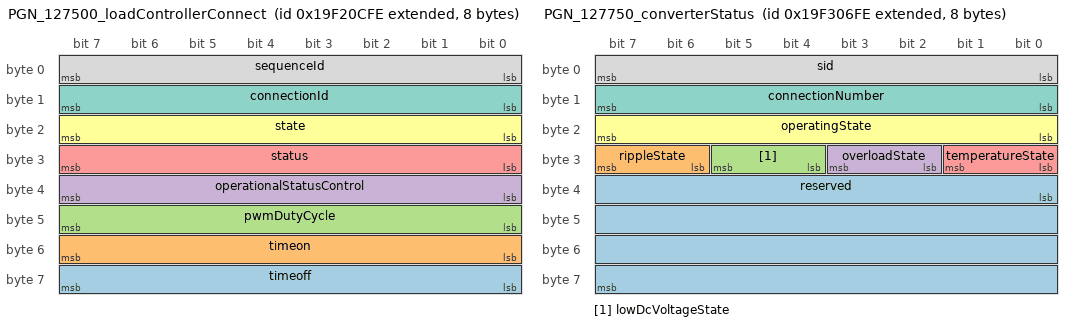
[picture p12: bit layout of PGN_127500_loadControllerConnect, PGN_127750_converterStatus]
BO_ 2582777086 PGN_127500_loadControllerConnect: 8 Vector__XXX
 SG_ timeoff : 56|8@1+ (1,0) [0|0] "" Vector__XXX
 SG_ timeon : 48|8@1+ (1,0) [0|0] "" Vector__XXX
 SG_ pwmDutyCycle : 40|8@1+ (1,0) [0|0] "" Vector__XXX
 SG_ operationalStatusControl : 32|8@1+ (1,0) [0|0] "" Vector__XXX
 SG_ status : 24|8@1+ (1,0) [0|0] "" Vector__XXX
 SG_ state : 16|8@1+ (1,0) [0|0] "" Vector__XXX
 SG_ connectionId : 8|8@1+ (1,0) [0|0] "" Vector__XXX
 SG_ sequenceId : 0|8@1+ (1,0) [0|0] "" Vector__XXX

BO_ 2582777342 PGN_127501_binarySwitchBankStatu: 8 Vector__XXX
 SG_ indicator28 : 62|2@1+ (1,0) [0|0] "" Vector__XXX
 SG_ indicator27 : 60|2@1+ (1,0) [0|0] "" Vector__XXX
 SG_ indicator26 : 58|2@1+ (1,0) [0|0] "" Vector__XXX
 SG_ indicator25 : 56|2@1+ (1,0) [0|0] "" Vector__XXX
 SG_ indicator24 : 54|2@1+ (1,0) [0|0] "" Vector__XXX
 SG_ indicator23 : 52|2@1+ (1,0) [0|0] "" Vector__XXX
 SG_ indicator22 : 50|2@1+ (1,0) [0|0] "" Vector__XXX
 SG_ indicator21 : 48|2@1+ (1,0) [0|0] "" Vector__XXX
 SG_ indicator20 : 46|2@1+ (1,0) [0|0] "" Vector__XXX
 SG_ indicator19 : 44|2@1+ (1,0) [0|0] "" Vector__XXX
 SG_ indicator18 : 42|2@1+ (1,0) [0|0] "" Vector__XXX
 SG_ indicator17 : 40|2@1+ (1,0) [0|0] "" Vector__XXX
 SG_ indicator16 : 38|2@1+ (1,0) [0|0] "" Vector__XXX
 SG_ indicator15 : 36|2@1+ (1,0) [0|0] "" Vector__XXX
 SG_ indicator14 : 34|2@1+ (1,0) [0|0] "" Vector__XXX
 SG_ indicator13 : 32|2@1+ (1,0) [0|0] "" Vector__XXX
 SG_ indicator12 : 30|2@1+ (1,0) [0|0] "" Vector__XXX
 SG_ indicator11 : 28|2@1+ (1,0) [0|0] "" Vector__XXX
 SG_ indicator10 : 26|2@1+ (1,0) [0|0] "" Vector__XXX
 SG_ indicator9 : 24|2@1+ (1,0) [0|0] "" Vector__XXX
 SG_ indicator8 : 22|2@1+ (1,0) [0|0] "" Vector__XXX
 SG_ indicator7 : 20|2@1+ (1,0) [0|0] "" Vector__XXX
 SG_ indicator6 : 18|2@1+ (1,0) [0|0] "" Vector__XXX
 SG_ indicator5 : 16|2@1+ (1,0) [0|0] "" Vector__XXX
 SG_ indicator4 : 14|2@1+ (1,0) [0|0] "" Vector__XXX
 SG_ indicator3 : 12|2@1+ (1,0) [0|0] "" Vector__XXX
 SG_ indicator2 : 10|2@1+ (1,0) [0|0] "" Vector__XXX
 SG_ indicator1 : 8|2@1+ (1,0) [0|0] "" Vector__XXX
 SG_ instance : 0|8@1+ (1,0) [0|0] "" Vector__XXX

BO_ 2582777598 PGN_127502_switchBankControl: 8 Vector__XXX
 SG_ switch28 : 62|2@1+ (1,0) [0|0] "" Vector__XXX
 SG_ switch27 : 60|2@1+ (1,0) [0|0] "" Vector__XXX
 SG_ switch26 : 58|2@1+ (1,0) [0|0] "" Vector__XXX
 SG_ switch25 : 56|2@1+ (1,0) [0|0] "" Vector__XXX
 SG_ switch24 : 54|2@1+ (1,0) [0|0] "" Vector__XXX
 SG_ switch23 : 52|2@1+ (1,0) [0|0] "" Vector__XXX
 SG_ switch22 : 50|2@1+ (1,0) [0|0] "" Vector__XXX
 SG_ switch21 : 48|2@1+ (1,0) [0|0] "" Vector__XXX
 SG_ switch20 : 46|2@1+ (1,0) [0|0] "" Vector__XXX
 SG_ switch19 : 44|2@1+ (1,0) [0|0] "" Vector__XXX
 SG_ switch18 : 42|2@1+ (1,0) [0|0] "" Vector__XXX
 SG_ switch17 : 40|2@1+ (1,0) [0|0] "" Vector__XXX
 SG_ switch16 : 38|2@1+ (1,0) [0|0] "" Vector__XXX
 SG_ switch15 : 36|2@1+ (1,0) [0|0] "" Vector__XXX
 SG_ switch14 : 34|2@1+ (1,0) [0|0] "" Vector__XXX
 SG_ switch13 : 32|2@1+ (1,0) [0|0] "" Vector__XXX
 SG_ switch12 : 30|2@1+ (1,0) [0|0] "" Vector__XXX
 SG_ switch11 : 28|2@1+ (1,0) [0|0] "" Vector__XXX
 SG_ switch10 : 26|2@1+ (1,0) [0|0] "" Vector__XXX
 SG_ switch9 : 24|2@1+ (1,0) [0|0] "" Vector__XXX
 SG_ switch8 : 22|2@1+ (1,0) [0|0] "" Vector__XXX
 SG_ switch7 : 20|2@1+ (1,0) [0|0] "" Vector__XXX
 SG_ switch6 : 18|2@1+ (1,0) [0|0] "" Vector__XXX
 SG_ switch5 : 16|2@1+ (1,0) [0|0] "" Vector__XXX
 SG_ switch4 : 14|2@1+ (1,0) [0|0] "" Vector__XXX
 SG_ switch3 : 12|2@1+ (1,0) [0|0] "" Vector__XXX
 SG_ switch2 : 10|2@1+ (1,0) [0|0] "" Vector__XXX
 SG_ switch1 : 8|2@1+ (1,0) [0|0] "" Vector__XXX
 SG_ instance : 0|8@1+ (1,0) [0|0] "" Vector__XXX

BO_ 2582777854 PGN_127503_acInputStatus: 8 Vector__XXX
 SG_ fastPacketData : 8|56@1+ (1,0) [0|0] "" Vector__XXX
 SG_ fastPacketSequenceCounter : 0|8@1+ (1,0) [0|0] "" Vector__XXX

BO_ 2582778110 PGN_127504_acOutputStatus: 8 Vector__XXX
 SG_ fastPacketData : 8|56@1+ (1,0) [0|0] "" Vector__XXX
 SG_ fastPacketSequenceCounter : 0|8@1+ (1,0) [0|0] "" Vector__XXX

BO_ 2582778366 PGN_127505_fluidLevel: 8 Vector__XXX
 SG_ reserved : 56|8@1+ (1,0) [0|0] "" Vector__XXX
 SG_ capacity : 24|32@1+ (0.1,0) [0|0] "L" Vector__XXX
 SG_ level : 8|16@1- (0.004,0) [0|0] "%" Vector__XXX
 SG_ type : 4|4@1+ (1,0) [0|0] "" Vector__XXX
 SG_ instance : 0|4@1+ (1,0) [0|0] "" Vector__XXX

BO_ 2582778622 PGN_127506_dcDetailedStatus: 8 Vector__XXX
 SG_ fastPacketData : 8|56@1+ (1,0) [0|0] "" Vector__XXX
 SG_ fastPacketSequenceCounter : 0|8@1+ (1,0) [0|0] "" Vector__XXX

BO_ 2582778878 PGN_127507_chargerStatus: 8 Vector__XXX
 SG_ fastPacketData : 8|56@1+ (1,0) [0|0] "" Vector__XXX
 SG_ fastPacketSequenceCounter : 0|8@1+ (1,0) [0|0] "" Vector__XXX

BO_ 2582779134 PGN_127508_batteryStatus: 8 Vector__XXX
 SG_ sid : 56|8@1+ (1,0) [0|0] "" Vector__XXX
 SG_ temperature : 40|16@1+ (0.01,0) [0|0] "K" Vector__XXX
 SG_ current : 24|16@1- (0.1,0) [0|0] "A" Vector__XXX
 SG_ voltage : 8|16@1- (0.01,0) [0|0] "V" Vector__XXX
 SG_ instance : 0|8@1+ (1,0) [0|0] "" Vector__XXX

BO_ 2582779390 PGN_127509_inverterStatus: 8 Vector__XXX
 SG_ fastPacketData : 8|56@1+ (1,0) [0|0] "" Vector__XXX
 SG_ fastPacketSequenceCounter : 0|8@1+ (1,0) [0|0] "" Vector__XXX

BO_ 2582779646 PGN_127510_chargerConfigurationS: 8 Vector__XXX
 SG_ fastPacketData : 8|56@1+ (1,0) [0|0] "" Vector__XXX
 SG_ fastPacketSequenceCounter : 0|8@1+ (1,0) [0|0] "" Vector__XXX

BO_ 2582779902 PGN_127511_inverterConfiguration: 8 Vector__XXX
 SG_ fastPacketData : 8|56@1+ (1,0) [0|0] "" Vector__XXX
 SG_ fastPacketSequenceCounter : 0|8@1+ (1,0) [0|0] "" Vector__XXX

BO_ 2582780158 PGN_127512_agsConfigurationStatu: 8 Vector__XXX
 SG_ fastPacketData : 8|56@1+ (1,0) [0|0] "" Vector__XXX
 SG_ fastPacketSequenceCounter : 0|8@1+ (1,0) [0|0] "" Vector__XXX

BO_ 2582780414 PGN_127513_batteryConfigurationS: 8 Vector__XXX
 SG_ fastPacketData : 8|56@1+ (1,0) [0|0] "" Vector__XXX
 SG_ fastPacketSequenceCounter : 0|8@1+ (1,0) [0|0] "" Vector__XXX

BO_ 2582780670 PGN_127514_agsStatus: 8 Vector__XXX
 SG_ fastPacketData : 8|56@1+ (1,0) [0|0] "" Vector__XXX
 SG_ fastPacketSequenceCounter : 0|8@1+ (1,0) [0|0] "" Vector__XXX

BO_ 2582839550 PGN_127744_acPowerCurrentPhaseA: 8 Vector__XXX
 SG_ power : 32|32@1- (1,0) [0|0] "W" Vector__XXX
 SG_ acRmsCurrent : 16|16@1+ (0.1,0) [0|0] "A" Vector__XXX
 SG_ connectionNumber : 8|8@1+ (1,0) [0|0] "" Vector__XXX
 SG_ sid : 0|8@1+ (1,0) [0|0] "" Vector__XXX

BO_ 2582839806 PGN_127745_acPowerCurrentPhaseB: 8 Vector__XXX
 SG_ power : 32|32@1- (1,0) [0|0] "W" Vector__XXX
 SG_ acRmsCurrent : 16|16@1+ (0.1,0) [0|0] "A" Vector__XXX
 SG_ connectionNumber : 8|8@1+ (1,0) [0|0] "" Vector__XXX
 SG_ sid : 0|8@1+ (1,0) [0|0] "" Vector__XXX

BO_ 2582840062 PGN_127746_acPowerCurrentPhaseC: 8 Vector__XXX
 SG_ power : 32|32@1- (1,0) [0|0] "W" Vector__XXX
 SG_ acRmsCurrent : 16|16@1+ (0.1,0) [0|0] "A" Vector__XXX
 SG_ connectionNumber : 8|8@1+ (1,0) [0|0] "" Vector__XXX
 SG_ sid : 0|8@1+ (1,0) [0|0] "" Vector__XXX

BO_ 2582840318 PGN_127747_acVoltageFrequencyPha: 8 Vector__XXX
 SG_ frequency : 48|16@1+ (0.1,0) [0|0] "Hz" Vector__XXX
 SG_ acVoltageLineToLine : 32|16@1+ (0.1,0) [0|0] "V" Vector__XXX
 SG_ acVoltageLineToNeutral : 16|16@1+ (0.1,0) [0|0] "V" Vector__XXX
 SG_ connectionNumber : 8|8@1+ (1,0) [0|0] "" Vector__XXX
 SG_ sid : 0|8@1+ (1,0) [0|0] "" Vector__XXX

BO_ 2582840574 PGN_127748_acVoltageFrequencyPha: 8 Vector__XXX
 SG_ frequency : 48|16@1+ (0.1,0) [0|0] "Hz" Vector__XXX
 SG_ acVoltageLineToLine : 32|16@1+ (0.1,0) [0|0] "V" Vector__XXX
 SG_ acVoltageLineToNeutral : 16|16@1+ (0.1,0) [0|0] "V" Vector__XXX
 SG_ connectionNumber : 8|8@1+ (1,0) [0|0] "" Vector__XXX
 SG_ sid : 0|8@1+ (1,0) [0|0] "" Vector__XXX

BO_ 2582840830 PGN_127749_acVoltageFrequencyPha: 8 Vector__XXX
 SG_ frequency : 48|16@1+ (0.1,0) [0|0] "Hz" Vector__XXX
 SG_ acVoltageLineToLine : 32|16@1+ (0.1,0) [0|0] "V" Vector__XXX
 SG_ acVoltageLineToNeutral : 16|16@1+ (0.1,0) [0|0] "V" Vector__XXX
 SG_ connectionNumber : 8|8@1+ (1,0) [0|0] "" Vector__XXX
 SG_ sid : 0|8@1+ (1,0) [0|0] "" Vector__XXX

BO_ 2582841086 PGN_127750_converterStatus: 8 Vector__XXX
 SG_ reserved : 32|32@1+ (1,0) [0|0] "" Vector__XXX
 SG_ rippleState : 30|2@1+ (1,0) [0|0] "" Vector__XXX
 SG_ lowDcVoltageState : 28|2@1+ (1,0) [0|0] "" Vector__XXX
 SG_ overloadState : 26|2@1+ (1,0) [0|0] "" Vector__XXX
 SG_ temperatureState : 24|2@1+ (1,0) [0|0] "" Vector__XXX
 SG_ operatingState : 16|8@1+ (1,0) [0|0] "" Vector__XXX
 SG_ connectionNumber : 8|8@1+ (1,0) [0|0] "" Vector__XXX
 SG_ sid : 0|8@1+ (1,0) [0|0] "" Vector__XXX

BO_ 2582841342 PGN_127751_dcVoltageCurrent: 8 Vector__XXX
 SG_ reserved : 56|8@1+ (1,0) [0|0] "" Vector__XXX
 SG_ dcCurrent : 32|24@1- (0.01,0) [0|0] "A" Vector__XXX
 SG_ dcVoltage : 16|16@1+ (0.1,0) [0|0] "V" Vector__XXX
 SG_ connectionNumber : 8|8@1+ (1,0) [0|0] "" Vector__XXX
 SG_ sid : 0|8@1+ (1,0) [0|0] "" Vector__XXX

BO_ 2582905086 PGN_128000_leewayAngle: 8 Vector__XXX
 SG_ reserved : 24|40@1+ (1,0) [0|0] "" Vector__XXX
 SG_ leewayAngle : 8|16@1- (0.0001,0) [0|0] "rad" Vector__XXX
 SG_ sid : 0|8@1+ (1,0) [0|0] "" Vector__XXX

BO_ 2582905342 PGN_128001_vesselAcceleration: 8 Vector__XXX
 SG_ reserved : 56|8@1+ (1,0) [0|0] "" Vector__XXX
 SG_ verticalAcceleration : 40|16@1- (1,0) [0|0] "" Vector__XXX
 SG_ transverseAcceleration : 24|16@1- (1,0) [0|0] "" Vector__XXX
 SG_ longitudinalAcceleration : 8|16@1- (1,0) [0|0] "" Vector__XXX
 SG_ sid : 0|8@1+ (1,0) [0|0] "" Vector__XXX

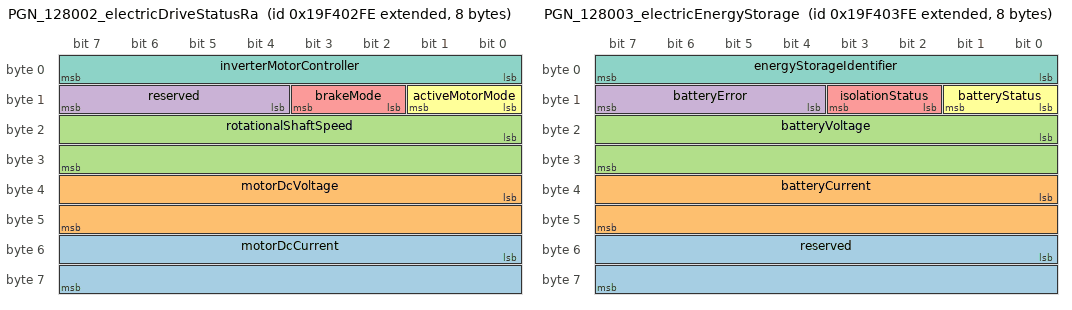
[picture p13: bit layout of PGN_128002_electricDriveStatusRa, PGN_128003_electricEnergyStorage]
BO_ 2582905598 PGN_128002_electricDriveStatusRa: 8 Vector__XXX
 SG_ motorDcCurrent : 48|16@1- (0.1,0) [0|0] "A" Vector__XXX
 SG_ motorDcVoltage : 32|16@1+ (0.1,0) [0|0] "V" Vector__XXX
 SG_ rotationalShaftSpeed : 16|16@1+ (0.25,0) [0|0] "rpm" Vector__XXX
 SG_ reserved : 12|4@1+ (1,0) [0|0] "" Vector__XXX
 SG_ brakeMode : 10|2@1+ (1,0) [0|0] "" Vector__XXX
 SG_ activeMotorMode : 8|2@1+ (1,0) [0|0] "" Vector__XXX
 SG_ inverterMotorController : 0|8@1+ (1,0) [0|0] "" Vector__XXX

BO_ 2582905854 PGN_128003_electricEnergyStorage: 8 Vector__XXX
 SG_ reserved : 48|16@1+ (1,0) [0|0] "" Vector__XXX
 SG_ batteryCurrent : 32|16@1- (0.1,0) [0|0] "A" Vector__XXX
 SG_ batteryVoltage : 16|16@1+ (0.1,0) [0|0] "V" Vector__XXX
 SG_ batteryError : 12|4@1+ (1,0) [0|0] "" Vector__XXX
 SG_ isolationStatus : 10|2@1+ (1,0) [0|0] "" Vector__XXX
 SG_ batteryStatus : 8|2@1+ (1,0) [0|0] "" Vector__XXX
 SG_ energyStorageIdentifier : 0|8@1+ (1,0) [0|0] "" Vector__XXX

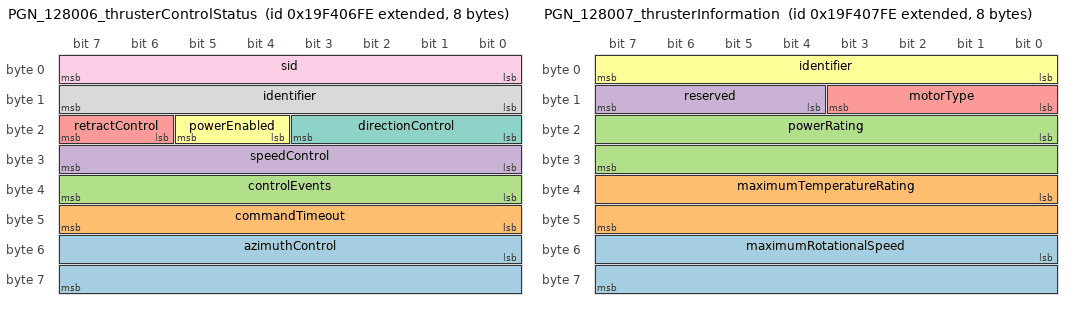
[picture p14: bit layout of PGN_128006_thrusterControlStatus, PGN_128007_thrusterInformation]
BO_ 2582906622 PGN_128006_thrusterControlStatus: 8 Vector__XXX
 SG_ azimuthControl : 48|16@1+ (0.0001,0) [0|0] "rad" Vector__XXX
 SG_ commandTimeout : 40|8@1+ (0.005,0) [0|0] "s" Vector__XXX
 SG_ controlEvents : 32|8@1+ (1,0) [0|0] "" Vector__XXX
 SG_ speedControl : 24|8@1+ (1,0) [0|0] "%" Vector__XXX
 SG_ retractControl : 22|2@1+ (1,0) [0|0] "" Vector__XXX
 SG_ powerEnabled : 20|2@1+ (1,0) [0|0] "" Vector__XXX
 SG_ directionControl : 16|4@1+ (1,0) [0|0] "" Vector__XXX
 SG_ identifier : 8|8@1+ (1,0) [0|0] "" Vector__XXX
 SG_ sid : 0|8@1+ (1,0) [0|0] "" Vector__XXX

BO_ 2582906878 PGN_128007_thrusterInformation: 8 Vector__XXX
 SG_ maximumRotationalSpeed : 48|16@1+ (0.25,0) [0|0] "rpm" Vector__XXX
 SG_ maximumTemperatureRating : 32|16@1+ (0.01,0) [0|0] "K" Vector__XXX
 SG_ powerRating : 16|16@1+ (1,0) [0|0] "W" Vector__XXX
 SG_ reserved : 12|4@1+ (1,0) [0|0] "" Vector__XXX
 SG_ motorType : 8|4@1+ (1,0) [0|0] "" Vector__XXX
 SG_ identifier : 0|8@1+ (1,0) [0|0] "" Vector__XXX

BO_ 2582907134 PGN_128008_thrusterMotorStatus: 8 Vector__XXX
 SG_ operatingTime : 48|16@1+ (60,0) [0|0] "s" Vector__XXX
 SG_ temperature : 32|16@1+ (0.01,0) [0|0] "K" Vector__XXX
 SG_ current : 24|8@1+ (1,0) [0|0] "A" Vector__XXX
 SG_ motorEvents : 16|8@1+ (1,0) [0|0] "" Vector__XXX
 SG_ identifier : 8|8@1+ (1,0) [0|0] "" Vector__XXX
 SG_ sid : 0|8@1+ (1,0) [0|0] "" Vector__XXX

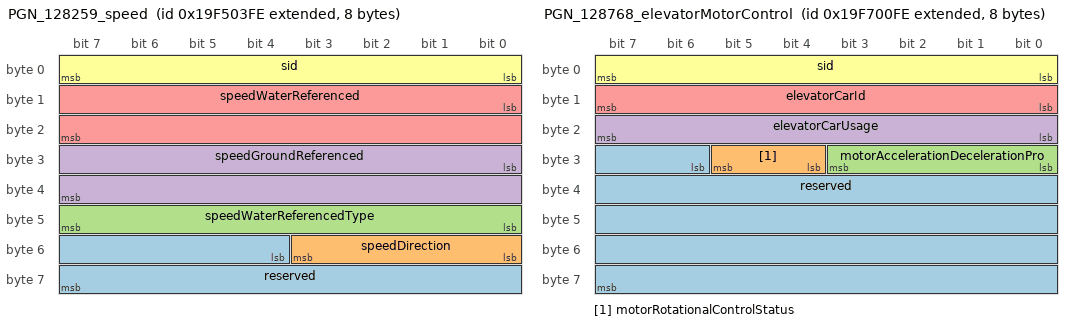
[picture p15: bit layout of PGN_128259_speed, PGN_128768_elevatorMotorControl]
BO_ 2582971390 PGN_128259_speed: 8 Vector__XXX
 SG_ reserved : 52|12@1+ (1,0) [0|0] "" Vector__XXX
 SG_ speedDirection : 48|4@1+ (1,0) [0|0] "" Vector__XXX
 SG_ speedWaterReferencedType : 40|8@1+ (1,0) [0|0] "" Vector__XXX
 SG_ speedGroundReferenced : 24|16@1+ (0.01,0) [0|0] "m/s" Vector__XXX
 SG_ speedWaterReferenced : 8|16@1+ (0.01,0) [0|0] "m/s" Vector__XXX
 SG_ sid : 0|8@1+ (1,0) [0|0] "" Vector__XXX

BO_ 2582973438 PGN_128267_waterDepth: 8 Vector__XXX
 SG_ range : 56|8@1+ (10,0) [0|0] "m" Vector__XXX
 SG_ offset : 40|16@1- (0.001,0) [0|0] "m" Vector__XXX
 SG_ depth : 8|32@1+ (0.01,0) [0|0] "m" Vector__XXX
 SG_ sid : 0|8@1+ (1,0) [0|0] "" Vector__XXX

BO_ 2582975486 PGN_128275_distanceLog: 8 Vector__XXX
 SG_ fastPacketData : 8|56@1+ (1,0) [0|0] "" Vector__XXX
 SG_ fastPacketSequenceCounter : 0|8@1+ (1,0) [0|0] "" Vector__XXX

BO_ 2583038206 PGN_128520_trackedTargetData: 8 Vector__XXX
 SG_ fastPacketData : 8|56@1+ (1,0) [0|0] "" Vector__XXX
 SG_ fastPacketSequenceCounter : 0|8@1+ (1,0) [0|0] "" Vector__XXX

BO_ 2583042814 PGN_128538_elevatorCarStatus: 8 Vector__XXX
 SG_ fastPacketData : 8|56@1+ (1,0) [0|0] "" Vector__XXX
 SG_ fastPacketSequenceCounter : 0|8@1+ (1,0) [0|0] "" Vector__XXX

BO_ 2583101694 PGN_128768_elevatorMotorControl: 8 Vector__XXX
 SG_ reserved : 30|34@1+ (1,0) [0|0] "" Vector__XXX
 SG_ motorRotationalControlStatus : 28|2@1+ (1,0) [0|0] "" Vector__XXX
 SG_ motorAccelerationDecelerationPro : 24|4@1+ (1,0) [0|0] "" Vector__XXX
 SG_ elevatorCarUsage : 16|8@1+ (1,0) [0|0] "" Vector__XXX
 SG_ elevatorCarId : 8|8@1+ (1,0) [0|0] "" Vector__XXX
 SG_ sid : 0|8@1+ (1,0) [0|0] "" Vector__XXX

BO_ 2583101950 PGN_128769_elevatorDeckPushButto: 8 Vector__XXX
 SG_ reserved : 40|24@1+ (1,0) [0|0] "" Vector__XXX
 SG_ elevatorCarButtonSelection : 32|8@1+ (1,0) [0|0] "" Vector__XXX
 SG_ elevatorCarUsage : 24|8@1+ (1,0) [0|0] "" Vector__XXX
 SG_ deckButtonId : 16|8@1+ (1,0) [0|0] "" Vector__XXX
 SG_ elevatorCallButtonId : 8|8@1+ (1,0) [0|0] "" Vector__XXX
 SG_ sid : 0|8@1+ (1,0) [0|0] "" Vector__XXX

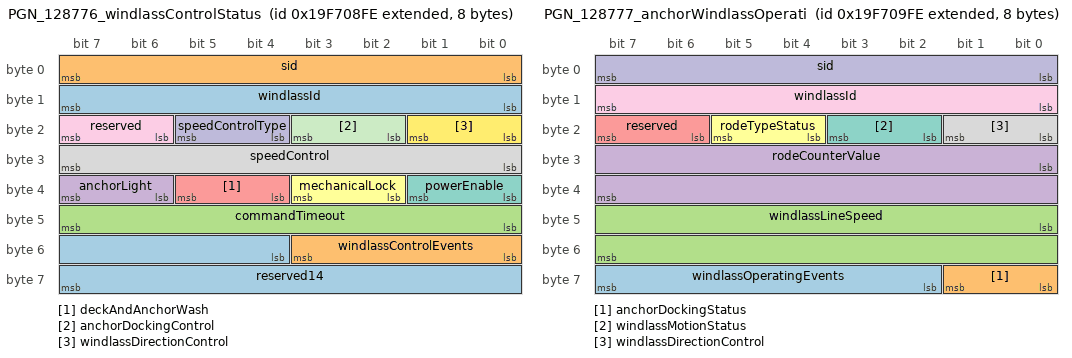
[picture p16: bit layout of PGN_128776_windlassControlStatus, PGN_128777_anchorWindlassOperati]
BO_ 2583103742 PGN_128776_windlassControlStatus: 8 Vector__XXX
 SG_ reserved14 : 52|12@1+ (1,0) [0|0] "" Vector__XXX
 SG_ windlassControlEvents : 48|4@1+ (1,0) [0|0] "" Vector__XXX
 SG_ commandTimeout : 40|8@1+ (0.005,0) [0|0] "s" Vector__XXX
 SG_ anchorLight : 38|2@1+ (1,0) [0|0] "" Vector__XXX
 SG_ deckAndAnchorWash : 36|2@1+ (1,0) [0|0] "" Vector__XXX
 SG_ mechanicalLock : 34|2@1+ (1,0) [0|0] "" Vector__XXX
 SG_ powerEnable : 32|2@1+ (1,0) [0|0] "" Vector__XXX
 SG_ speedControl : 24|8@1+ (1,0) [0|0] "" Vector__XXX
 SG_ reserved : 22|2@1+ (1,0) [0|0] "" Vector__XXX
 SG_ speedControlType : 20|2@1+ (1,0) [0|0] "" Vector__XXX
 SG_ anchorDockingControl : 18|2@1+ (1,0) [0|0] "" Vector__XXX
 SG_ windlassDirectionControl : 16|2@1+ (1,0) [0|0] "" Vector__XXX
 SG_ windlassId : 8|8@1+ (1,0) [0|0] "" Vector__XXX
 SG_ sid : 0|8@1+ (1,0) [0|0] "" Vector__XXX

BO_ 2583103998 PGN_128777_anchorWindlassOperati: 8 Vector__XXX
 SG_ windlassOperatingEvents : 58|6@1+ (1,0) [0|0] "" Vector__XXX
 SG_ anchorDockingStatus : 56|2@1+ (1,0) [0|0] "" Vector__XXX
 SG_ windlassLineSpeed : 40|16@1+ (0.01,0) [0|0] "m/s" Vector__XXX
 SG_ rodeCounterValue : 24|16@1+ (0.1,0) [0|0] "m" Vector__XXX
 SG_ reserved : 22|2@1+ (1,0) [0|0] "" Vector__XXX
 SG_ rodeTypeStatus : 20|2@1+ (1,0) [0|0] "" Vector__XXX
 SG_ windlassMotionStatus : 18|2@1+ (1,0) [0|0] "" Vector__XXX
 SG_ windlassDirectionControl : 16|2@1+ (1,0) [0|0] "" Vector__XXX
 SG_ windlassId : 8|8@1+ (1,0) [0|0] "" Vector__XXX
 SG_ sid : 0|8@1+ (1,0) [0|0] "" Vector__XXX

BO_ 2583104254 PGN_128778_anchorWindlassMonitor: 8 Vector__XXX
 SG_ reserved : 56|8@1+ (1,0) [0|0] "" Vector__XXX
 SG_ totalMotorTime : 40|16@1+ (60,0) [0|0] "s" Vector__XXX
 SG_ motorCurrent : 32|8@1+ (1,0) [0|0] "A" Vector__XXX
 SG_ controllerVoltage : 24|8@1+ (0.2,0) [0|0] "V" Vector__XXX
 SG_ windlassMonitoringEvents : 16|8@1+ (1,0) [0|0] "" Vector__XXX
 SG_ windlassId : 8|8@1+ (1,0) [0|0] "" Vector__XXX
 SG_ sid : 0|8@1+ (1,0) [0|0] "" Vector__XXX

BO_ 2583104766 PGN_128780_linearActuatorControl: 8 Vector__XXX
 SG_ reserved : 48|16@1+ (1,0) [0|0] "" Vector__XXX
 SG_ directionOfTravel : 40|8@1+ (1,0) [0|0] "" Vector__XXX
 SG_ maximumDeviceTravel : 24|16@1+ (1,0) [0|0] "" Vector__XXX
 SG_ devicePosition : 16|8@1+ (1,0) [0|0] "" Vector__XXX
 SG_ commandedDevicePosition : 8|8@1+ (1,0) [0|0] "" Vector__XXX
 SG_ actuatorIdentifier : 0|8@1+ (1,0) [0|0] "" Vector__XXX

BO_ 2583167486 PGN_129025_positionRapidUpdate: 8 Vector__XXX
 SG_ longitude : 32|32@1- (1e-07,0) [0|0] "deg" Vector__XXX
 SG_ latitude : 0|32@1- (1e-07,0) [0|0] "deg" Vector__XXX

BO_ 2583167742 PGN_129026_cogSogRapidUpdate: 8 Vector__XXX
 SG_ reserved6 : 48|16@1+ (1,0) [0|0] "" Vector__XXX
 SG_ sog : 32|16@1+ (0.01,0) [0|0] "m/s" Vector__XXX
 SG_ cog : 16|16@1+ (0.0001,0) [0|0] "rad" Vector__XXX
 SG_ reserved : 10|6@1+ (1,0) [0|0] "" Vector__XXX
 SG_ cogReference : 8|2@1+ (1,0) [0|0] "" Vector__XXX
 SG_ sid : 0|8@1+ (1,0) [0|0] "" Vector__XXX

BO_ 2583167998 PGN_129027_positionDeltaRapidUpd: 8 Vector__XXX
 SG_ longitudeDelta : 40|24@1- (2.77778e-09,0) [0|0] "deg" Vector__XXX
 SG_ latitudeDelta : 16|24@1- (2.77778e-09,0) [0|0] "deg" Vector__XXX
 SG_ timeDelta : 8|8@1+ (0.005,0) [0|0] "s" Vector__XXX
 SG_ sid : 0|8@1+ (1,0) [0|0] "" Vector__XXX

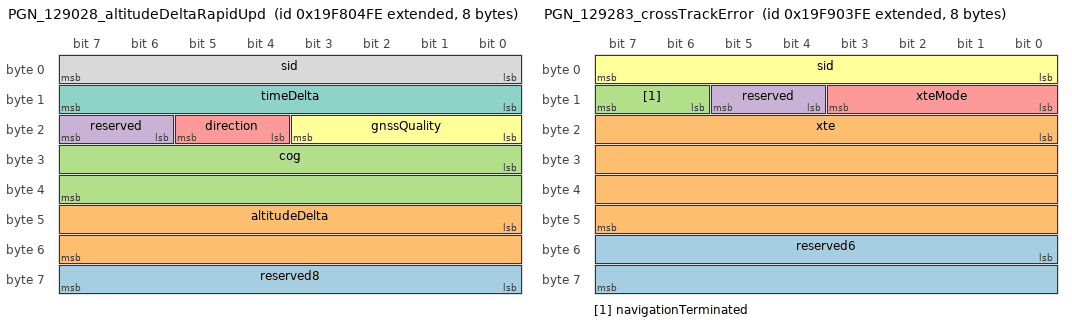
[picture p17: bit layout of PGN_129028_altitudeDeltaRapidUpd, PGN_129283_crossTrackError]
BO_ 2583168254 PGN_129028_altitudeDeltaRapidUpd: 8 Vector__XXX
 SG_ reserved8 : 56|8@1+ (1,0) [0|0] "" Vector__XXX
 SG_ altitudeDelta : 40|16@1- (0.001,0) [0|0] "m" Vector__XXX
 SG_ cog : 24|16@1+ (0.0001,0) [0|0] "rad" Vector__XXX
 SG_ reserved : 22|2@1+ (1,0) [0|0] "" Vector__XXX
 SG_ direction : 20|2@1+ (1,0) [0|0] "" Vector__XXX
 SG_ gnssQuality : 16|4@1+ (1,0) [0|0] "" Vector__XXX
 SG_ timeDelta : 8|8@1+ (0.005,0) [0|0] "s" Vector__XXX
 SG_ sid : 0|8@1+ (1,0) [0|0] "" Vector__XXX

BO_ 2583168510 PGN_129029_gnssPositionData: 8 Vector__XXX
 SG_ fastPacketData : 8|56@1+ (1,0) [0|0] "" Vector__XXX
 SG_ fastPacketSequenceCounter : 0|8@1+ (1,0) [0|0] "" Vector__XXX

BO_ 2583169534 PGN_129033_timeDate: 8 Vector__XXX
 SG_ localOffset : 48|16@1- (60,0) [0|0] "s" Vector__XXX
 SG_ time : 16|32@1+ (0.0001,0) [0|0] "s" Vector__XXX
 SG_ date : 0|16@1+ (1,0) [0|0] "d" Vector__XXX

BO_ 2583170814 PGN_129038_aisClassAPositionRepo: 8 Vector__XXX
 SG_ fastPacketData : 8|56@1+ (1,0) [0|0] "" Vector__XXX
 SG_ fastPacketSequenceCounter : 0|8@1+ (1,0) [0|0] "" Vector__XXX

BO_ 2583171070 PGN_129039_aisClassBPositionRepo: 8 Vector__XXX
 SG_ fastPacketData : 8|56@1+ (1,0) [0|0] "" Vector__XXX
 SG_ fastPacketSequenceCounter : 0|8@1+ (1,0) [0|0] "" Vector__XXX

BO_ 2583171326 PGN_129040_aisClassBExtendedPosi: 8 Vector__XXX
 SG_ fastPacketData : 8|56@1+ (1,0) [0|0] "" Vector__XXX
 SG_ fastPacketSequenceCounter : 0|8@1+ (1,0) [0|0] "" Vector__XXX

BO_ 2583171582 PGN_129041_aisAidsToNavigationAt: 8 Vector__XXX
 SG_ fastPacketData : 8|56@1+ (1,0) [0|0] "" Vector__XXX
 SG_ fastPacketSequenceCounter : 0|8@1+ (1,0) [0|0] "" Vector__XXX

BO_ 2583172350 PGN_129044_datum: 8 Vector__XXX
 SG_ fastPacketData : 8|56@1+ (1,0) [0|0] "" Vector__XXX
 SG_ fastPacketSequenceCounter : 0|8@1+ (1,0) [0|0] "" Vector__XXX

BO_ 2583172606 PGN_129045_userDatum: 8 Vector__XXX
 SG_ fastPacketData : 8|56@1+ (1,0) [0|0] "" Vector__XXX
 SG_ fastPacketSequenceCounter : 0|8@1+ (1,0) [0|0] "" Vector__XXX

BO_ 2583233534 PGN_129283_crossTrackError: 8 Vector__XXX
 SG_ reserved6 : 48|16@1+ (1,0) [0|0] "" Vector__XXX
 SG_ xte : 16|32@1- (0.01,0) [0|0] "m" Vector__XXX
 SG_ navigationTerminated : 14|2@1+ (1,0) [0|0] "" Vector__XXX
 SG_ reserved : 12|2@1+ (1,0) [0|0] "" Vector__XXX
 SG_ xteMode : 8|4@1+ (1,0) [0|0] "" Vector__XXX
 SG_ sid : 0|8@1+ (1,0) [0|0] "" Vector__XXX

BO_ 2583233790 PGN_129284_navigationData: 8 Vector__XXX
 SG_ fastPacketData : 8|56@1+ (1,0) [0|0] "" Vector__XXX
 SG_ fastPacketSequenceCounter : 0|8@1+ (1,0) [0|0] "" Vector__XXX

BO_ 2583234046 PGN_129285_navigationRouteWpInfo: 8 Vector__XXX
 SG_ fastPacketData : 8|56@1+ (1,0) [0|0] "" Vector__XXX
 SG_ fastPacketSequenceCounter : 0|8@1+ (1,0) [0|0] "" Vector__XXX

BO_ 2583235582 PGN_129291_setDriftRapidUpdate: 8 Vector__XXX
 SG_ reserved6 : 48|16@1+ (1,0) [0|0] "" Vector__XXX
 SG_ drift : 32|16@1+ (0.01,0) [0|0] "m/s" Vector__XXX
 SG_ set : 16|16@1+ (0.0001,0) [0|0] "rad" Vector__XXX
 SG_ reserved : 10|6@1+ (1,0) [0|0] "" Vector__XXX
 SG_ setReference : 8|2@1+ (1,0) [0|0] "" Vector__XXX
 SG_ sid : 0|8@1+ (1,0) [0|0] "" Vector__XXX

BO_ 2583238142 PGN_129301_navigationRouteTimeTo: 8 Vector__XXX
 SG_ fastPacketData : 8|56@1+ (1,0) [0|0] "" Vector__XXX
 SG_ fastPacketSequenceCounter : 0|8@1+ (1,0) [0|0] "" Vector__XXX

BO_ 2583238398 PGN_129302_bearingAndDistanceBet: 8 Vector__XXX
 SG_ fastPacketData : 8|56@1+ (1,0) [0|0] "" Vector__XXX
 SG_ fastPacketSequenceCounter : 0|8@1+ (1,0) [0|0] "" Vector__XXX

BO_ 2583298814 PGN_129538_gnssControlStatus: 8 Vector__XXX
 SG_ fastPacketData : 8|56@1+ (1,0) [0|0] "" Vector__XXX
 SG_ fastPacketSequenceCounter : 0|8@1+ (1,0) [0|0] "" Vector__XXX

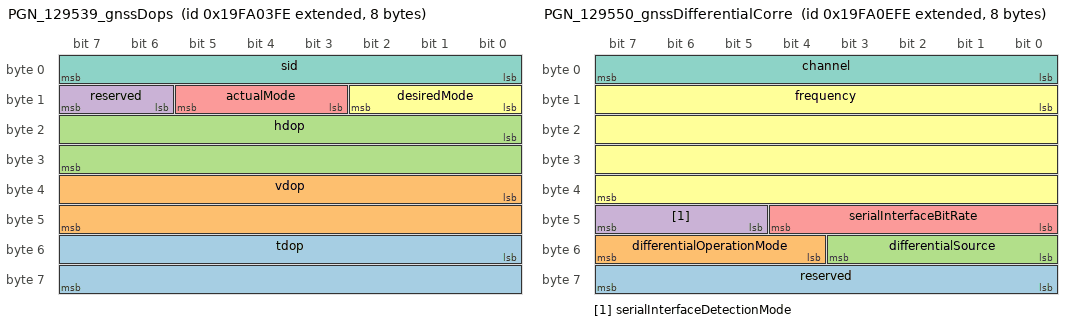
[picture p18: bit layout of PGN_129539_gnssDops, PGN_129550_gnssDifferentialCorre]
BO_ 2583299070 PGN_129539_gnssDops: 8 Vector__XXX
 SG_ tdop : 48|16@1- (0.01,0) [0|0] "" Vector__XXX
 SG_ vdop : 32|16@1- (0.01,0) [0|0] "" Vector__XXX
 SG_ hdop : 16|16@1- (0.01,0) [0|0] "" Vector__XXX
 SG_ reserved : 14|2@1+ (1,0) [0|0] "" Vector__XXX
 SG_ actualMode : 11|3@1+ (1,0) [0|0] "" Vector__XXX
 SG_ desiredMode : 8|3@1+ (1,0) [0|0] "" Vector__XXX
 SG_ sid : 0|8@1+ (1,0) [0|0] "" Vector__XXX

BO_ 2583299326 PGN_129540_gnssSatsInView: 8 Vector__XXX
 SG_ fastPacketData : 8|56@1+ (1,0) [0|0] "" Vector__XXX
 SG_ fastPacketSequenceCounter : 0|8@1+ (1,0) [0|0] "" Vector__XXX

BO_ 2583299582 PGN_129541_gpsAlmanacData: 8 Vector__XXX
 SG_ fastPacketData : 8|56@1+ (1,0) [0|0] "" Vector__XXX
 SG_ fastPacketSequenceCounter : 0|8@1+ (1,0) [0|0] "" Vector__XXX

BO_ 2583299838 PGN_129542_gnssPseudorangeNoiseS: 8 Vector__XXX
 SG_ fastPacketData : 8|56@1+ (1,0) [0|0] "" Vector__XXX
 SG_ fastPacketSequenceCounter : 0|8@1+ (1,0) [0|0] "" Vector__XXX

BO_ 2583300606 PGN_129545_gnssRaimOutput: 8 Vector__XXX
 SG_ fastPacketData : 8|56@1+ (1,0) [0|0] "" Vector__XXX
 SG_ fastPacketSequenceCounter : 0|8@1+ (1,0) [0|0] "" Vector__XXX

BO_ 2583300862 PGN_129546_gnssRaimSettings: 8 Vector__XXX
 SG_ reserved : 48|16@1+ (1,0) [0|0] "" Vector__XXX
 SG_ pseudorangeResidualFilteringTime : 32|16@1+ (1,0) [0|0] "s" Vector__XXX
 SG_ probabilityOfMissedDetection : 24|8@1- (1,0) [0|0] "%" Vector__XXX
 SG_ probabilityOfFalseAlarm : 16|8@1- (1,0) [0|0] "%" Vector__XXX
 SG_ radialPositionErrorMaximumThresh : 0|16@1- (0.01,0) [0|0] "m" Vector__XXX

BO_ 2583301118 PGN_129547_gnssPseudorangeErrorS: 8 Vector__XXX
 SG_ fastPacketData : 8|56@1+ (1,0) [0|0] "" Vector__XXX
 SG_ fastPacketSequenceCounter : 0|8@1+ (1,0) [0|0] "" Vector__XXX

BO_ 2583301630 PGN_129549_dgnssCorrections: 8 Vector__XXX
 SG_ fastPacketData : 8|56@1+ (1,0) [0|0] "" Vector__XXX
 SG_ fastPacketSequenceCounter : 0|8@1+ (1,0) [0|0] "" Vector__XXX

BO_ 2583301886 PGN_129550_gnssDifferentialCorre: 8 Vector__XXX
 SG_ reserved : 56|8@1+ (1,0) [0|0] "" Vector__XXX
 SG_ differentialOperationMode : 52|4@1+ (1,0) [0|0] "" Vector__XXX
 SG_ differentialSource : 48|4@1+ (1,0) [0|0] "" Vector__XXX
 SG_ serialInterfaceDetectionMode : 45|3@1+ (1,0) [0|0] "" Vector__XXX
 SG_ serialInterfaceBitRate : 40|5@1+ (1,0) [0|0] "" Vector__XXX
 SG_ frequency : 8|32@1+ (10,0) [0|0] "Hz" Vector__XXX
 SG_ channel : 0|8@1+ (1,0) [0|0] "" Vector__XXX

BO_ 2583302142 PGN_129551_gnssDifferentialCorre: 8 Vector__XXX
 SG_ fastPacketData : 8|56@1+ (1,0) [0|0] "" Vector__XXX
 SG_ fastPacketSequenceCounter : 0|8@1+ (1,0) [0|0] "" Vector__XXX

BO_ 2583303422 PGN_129556_glonassAlmanacData: 8 Vector__XXX
 SG_ fastPacketData : 8|56@1+ (1,0) [0|0] "" Vector__XXX
 SG_ fastPacketSequenceCounter : 0|8@1+ (1,0) [0|0] "" Vector__XXX

BO_ 2583363838 PGN_129792_aisDgnssBroadcastBina: 8 Vector__XXX
 SG_ fastPacketData : 8|56@1+ (1,0) [0|0] "" Vector__XXX
 SG_ fastPacketSequenceCounter : 0|8@1+ (1,0) [0|0] "" Vector__XXX

BO_ 2583364094 PGN_129793_aisUtcAndDateReport: 8 Vector__XXX
 SG_ fastPacketData : 8|56@1+ (1,0) [0|0] "" Vector__XXX
 SG_ fastPacketSequenceCounter : 0|8@1+ (1,0) [0|0] "" Vector__XXX

BO_ 2583364350 PGN_129794_aisClassAStaticAndVoy: 8 Vector__XXX
 SG_ fastPacketData : 8|56@1+ (1,0) [0|0] "" Vector__XXX
 SG_ fastPacketSequenceCounter : 0|8@1+ (1,0) [0|0] "" Vector__XXX

BO_ 2583364606 PGN_129795_aisAddressedBinaryMes: 8 Vector__XXX
 SG_ fastPacketData : 8|56@1+ (1,0) [0|0] "" Vector__XXX
 SG_ fastPacketSequenceCounter : 0|8@1+ (1,0) [0|0] "" Vector__XXX

BO_ 2583364862 PGN_129796_aisAcknowledge: 8 Vector__XXX
 SG_ fastPacketData : 8|56@1+ (1,0) [0|0] "" Vector__XXX
 SG_ fastPacketSequenceCounter : 0|8@1+ (1,0) [0|0] "" Vector__XXX

BO_ 2583365118 PGN_129797_aisBinaryBroadcastMes: 8 Vector__XXX
 SG_ fastPacketData : 8|56@1+ (1,0) [0|0] "" Vector__XXX
 SG_ fastPacketSequenceCounter : 0|8@1+ (1,0) [0|0] "" Vector__XXX

BO_ 2583365374 PGN_129798_aisSarAircraftPositio: 8 Vector__XXX
 SG_ fastPacketData : 8|56@1+ (1,0) [0|0] "" Vector__XXX
 SG_ fastPacketSequenceCounter : 0|8@1+ (1,0) [0|0] "" Vector__XXX

BO_ 2583365630 PGN_129799_radioFrequencyModePow: 8 Vector__XXX
 SG_ fastPacketData : 8|56@1+ (1,0) [0|0] "" Vector__XXX
 SG_ fastPacketSequenceCounter : 0|8@1+ (1,0) [0|0] "" Vector__XXX

BO_ 2583365886 PGN_129800_aisUtcDateInquiry: 8 Vector__XXX
 SG_ fastPacketData : 8|56@1+ (1,0) [0|0] "" Vector__XXX
 SG_ fastPacketSequenceCounter : 0|8@1+ (1,0) [0|0] "" Vector__XXX

BO_ 2583366142 PGN_129801_aisAddressedSafetyRel: 8 Vector__XXX
 SG_ fastPacketData : 8|56@1+ (1,0) [0|0] "" Vector__XXX
 SG_ fastPacketSequenceCounter : 0|8@1+ (1,0) [0|0] "" Vector__XXX

BO_ 2583366398 PGN_129802_aisSafetyRelatedBroad: 8 Vector__XXX
 SG_ fastPacketData : 8|56@1+ (1,0) [0|0] "" Vector__XXX
 SG_ fastPacketSequenceCounter : 0|8@1+ (1,0) [0|0] "" Vector__XXX

BO_ 2583366654 PGN_129803_aisInterrogation: 8 Vector__XXX
 SG_ fastPacketData : 8|56@1+ (1,0) [0|0] "" Vector__XXX
 SG_ fastPacketSequenceCounter : 0|8@1+ (1,0) [0|0] "" Vector__XXX

BO_ 2583366910 PGN_129804_aisAssignmentModeComm: 8 Vector__XXX
 SG_ fastPacketData : 8|56@1+ (1,0) [0|0] "" Vector__XXX
 SG_ fastPacketSequenceCounter : 0|8@1+ (1,0) [0|0] "" Vector__XXX

BO_ 2583367166 PGN_129805_aisDataLinkManagement: 8 Vector__XXX
 SG_ fastPacketData : 8|56@1+ (1,0) [0|0] "" Vector__XXX
 SG_ fastPacketSequenceCounter : 0|8@1+ (1,0) [0|0] "" Vector__XXX

BO_ 2583367422 PGN_129806_aisChannelManagement: 8 Vector__XXX
 SG_ fastPacketData : 8|56@1+ (1,0) [0|0] "" Vector__XXX
 SG_ fastPacketSequenceCounter : 0|8@1+ (1,0) [0|0] "" Vector__XXX

BO_ 2583367678 PGN_129807_aisClassBGroupAssignm: 8 Vector__XXX
 SG_ fastPacketData : 8|56@1+ (1,0) [0|0] "" Vector__XXX
 SG_ fastPacketSequenceCounter : 0|8@1+ (1,0) [0|0] "" Vector__XXX

BO_ 2583368190 PGN_129809_aisClassBStaticDataMs: 8 Vector__XXX
 SG_ fastPacketData : 8|56@1+ (1,0) [0|0] "" Vector__XXX
 SG_ fastPacketSequenceCounter : 0|8@1+ (1,0) [0|0] "" Vector__XXX

BO_ 2583368446 PGN_129810_aisClassBStaticDataMs: 8 Vector__XXX
 SG_ fastPacketData : 8|56@1+ (1,0) [0|0] "" Vector__XXX
 SG_ fastPacketSequenceCounter : 0|8@1+ (1,0) [0|0] "" Vector__XXX

BO_ 2583430398 PGN_130052_loranCTdData: 8 Vector__XXX
 SG_ fastPacketData : 8|56@1+ (1,0) [0|0] "" Vector__XXX
 SG_ fastPacketSequenceCounter : 0|8@1+ (1,0) [0|0] "" Vector__XXX

BO_ 2583430654 PGN_130053_loranCRangeData: 8 Vector__XXX
 SG_ fastPacketData : 8|56@1+ (1,0) [0|0] "" Vector__XXX
 SG_ fastPacketSequenceCounter : 0|8@1+ (1,0) [0|0] "" Vector__XXX

BO_ 2583430910 PGN_130054_loranCSignalData: 8 Vector__XXX
 SG_ fastPacketData : 8|56@1+ (1,0) [0|0] "" Vector__XXX
 SG_ fastPacketSequenceCounter : 0|8@1+ (1,0) [0|0] "" Vector__XXX

BO_ 2583432446 PGN_130060_label: 8 Vector__XXX
 SG_ fastPacketData : 8|56@1+ (1,0) [0|0] "" Vector__XXX
 SG_ fastPacketSequenceCounter : 0|8@1+ (1,0) [0|0] "" Vector__XXX

BO_ 2583432702 PGN_130061_channelSourceConfigur: 8 Vector__XXX
 SG_ fastPacketData : 8|56@1+ (1,0) [0|0] "" Vector__XXX
 SG_ fastPacketSequenceCounter : 0|8@1+ (1,0) [0|0] "" Vector__XXX

BO_ 2583433470 PGN_130064_routeAndWpServiceData: 8 Vector__XXX
 SG_ fastPacketData : 8|56@1+ (1,0) [0|0] "" Vector__XXX
 SG_ fastPacketSequenceCounter : 0|8@1+ (1,0) [0|0] "" Vector__XXX

BO_ 2583433726 PGN_130065_routeAndWpServiceRout: 8 Vector__XXX
 SG_ fastPacketData : 8|56@1+ (1,0) [0|0] "" Vector__XXX
 SG_ fastPacketSequenceCounter : 0|8@1+ (1,0) [0|0] "" Vector__XXX

BO_ 2583433982 PGN_130066_routeAndWpServiceRout: 8 Vector__XXX
 SG_ fastPacketData : 8|56@1+ (1,0) [0|0] "" Vector__XXX
 SG_ fastPacketSequenceCounter : 0|8@1+ (1,0) [0|0] "" Vector__XXX

BO_ 2583434238 PGN_130067_routeAndWpServiceRout: 8 Vector__XXX
 SG_ fastPacketData : 8|56@1+ (1,0) [0|0] "" Vector__XXX
 SG_ fastPacketSequenceCounter : 0|8@1+ (1,0) [0|0] "" Vector__XXX

BO_ 2583434494 PGN_130068_routeAndWpServiceRout: 8 Vector__XXX
 SG_ fastPacketData : 8|56@1+ (1,0) [0|0] "" Vector__XXX
 SG_ fastPacketSequenceCounter : 0|8@1+ (1,0) [0|0] "" Vector__XXX

BO_ 2583434750 PGN_130069_routeAndWpServiceXteL: 8 Vector__XXX
 SG_ fastPacketData : 8|56@1+ (1,0) [0|0] "" Vector__XXX
 SG_ fastPacketSequenceCounter : 0|8@1+ (1,0) [0|0] "" Vector__XXX

BO_ 2583435006 PGN_130070_routeAndWpServiceWpCo: 8 Vector__XXX
 SG_ fastPacketData : 8|56@1+ (1,0) [0|0] "" Vector__XXX
 SG_ fastPacketSequenceCounter : 0|8@1+ (1,0) [0|0] "" Vector__XXX

BO_ 2583435262 PGN_130071_routeAndWpServiceRout: 8 Vector__XXX
 SG_ fastPacketData : 8|56@1+ (1,0) [0|0] "" Vector__XXX
 SG_ fastPacketSequenceCounter : 0|8@1+ (1,0) [0|0] "" Vector__XXX

BO_ 2583435518 PGN_130072_routeAndWpServiceData: 8 Vector__XXX
 SG_ fastPacketData : 8|56@1+ (1,0) [0|0] "" Vector__XXX
 SG_ fastPacketSequenceCounter : 0|8@1+ (1,0) [0|0] "" Vector__XXX

BO_ 2583435774 PGN_130073_routeAndWpServiceRadi: 8 Vector__XXX
 SG_ fastPacketData : 8|56@1+ (1,0) [0|0] "" Vector__XXX
 SG_ fastPacketSequenceCounter : 0|8@1+ (1,0) [0|0] "" Vector__XXX

BO_ 2583436030 PGN_130074_routeAndWpServiceWpLi: 8 Vector__XXX
 SG_ fastPacketData : 8|56@1+ (1,0) [0|0] "" Vector__XXX
 SG_ fastPacketSequenceCounter : 0|8@1+ (1,0) [0|0] "" Vector__XXX

BO_ 2583495422 PGN_130306_windData: 8 Vector__XXX
 SG_ reserved : 43|21@1+ (1,0) [0|0] "" Vector__XXX
 SG_ reference : 40|3@1+ (1,0) [0|0] "" Vector__XXX
 SG_ windAngle : 24|16@1+ (0.0001,0) [0|0] "rad" Vector__XXX
 SG_ windSpeed : 8|16@1+ (0.01,0) [0|0] "m/s" Vector__XXX
 SG_ sid : 0|8@1+ (1,0) [0|0] "" Vector__XXX

BO_ 2583496446 PGN_130310_environmentalParamete: 8 Vector__XXX
 SG_ reserved : 56|8@1+ (1,0) [0|0] "" Vector__XXX
 SG_ atmosphericPressure : 40|16@1+ (100,0) [0|0] "Pa" Vector__XXX
 SG_ outsideAmbientAirTemperature : 24|16@1+ (0.01,0) [0|0] "K" Vector__XXX
 SG_ waterTemperature : 8|16@1+ (0.01,0) [0|0] "K" Vector__XXX
 SG_ sid : 0|8@1+ (1,0) [0|0] "" Vector__XXX

BO_ 2583496702 PGN_130311_environmentalParamete: 8 Vector__XXX
 SG_ atmosphericPressure : 48|16@1+ (100,0) [0|0] "Pa" Vector__XXX
 SG_ humidity : 32|16@1- (0.004,0) [0|0] "%" Vector__XXX
 SG_ temperature : 16|16@1+ (0.01,0) [0|0] "K" Vector__XXX
 SG_ humiditySource : 14|2@1+ (1,0) [0|0] "" Vector__XXX
 SG_ temperatureSource : 8|6@1+ (1,0) [0|0] "" Vector__XXX
 SG_ sid : 0|8@1+ (1,0) [0|0] "" Vector__XXX

BO_ 2583496958 PGN_130312_temperature: 8 Vector__XXX
 SG_ reserved : 56|8@1+ (1,0) [0|0] "" Vector__XXX
 SG_ setTemperature : 40|16@1+ (0.01,0) [0|0] "K" Vector__XXX
 SG_ actualTemperature : 24|16@1+ (0.01,0) [0|0] "K" Vector__XXX
 SG_ source : 16|8@1+ (1,0) [0|0] "" Vector__XXX
 SG_ instance : 8|8@1+ (1,0) [0|0] "" Vector__XXX
 SG_ sid : 0|8@1+ (1,0) [0|0] "" Vector__XXX

BO_ 2583497214 PGN_130313_humidity: 8 Vector__XXX
 SG_ reserved : 56|8@1+ (1,0) [0|0] "" Vector__XXX
 SG_ setHumidity : 40|16@1- (0.004,0) [0|0] "%" Vector__XXX
 SG_ actualHumidity : 24|16@1- (0.004,0) [0|0] "%" Vector__XXX
 SG_ source : 16|8@1+ (1,0) [0|0] "" Vector__XXX
 SG_ instance : 8|8@1+ (1,0) [0|0] "" Vector__XXX
 SG_ sid : 0|8@1+ (1,0) [0|0] "" Vector__XXX

BO_ 2583497470 PGN_130314_actualPressure: 8 Vector__XXX
 SG_ reserved : 56|8@1+ (1,0) [0|0] "" Vector__XXX
 SG_ pressure : 24|32@1- (0.1,0) [0|0] "Pa" Vector__XXX
 SG_ source : 16|8@1+ (1,0) [0|0] "" Vector__XXX
 SG_ instance : 8|8@1+ (1,0) [0|0] "" Vector__XXX
 SG_ sid : 0|8@1+ (1,0) [0|0] "" Vector__XXX

BO_ 2583497726 PGN_130315_setPressure: 8 Vector__XXX
 SG_ reserved : 56|8@1+ (1,0) [0|0] "" Vector__XXX
 SG_ pressure : 24|32@1+ (0.1,0) [0|0] "Pa" Vector__XXX
 SG_ source : 16|8@1+ (1,0) [0|0] "" Vector__XXX
 SG_ instance : 8|8@1+ (1,0) [0|0] "" Vector__XXX
 SG_ sid : 0|8@1+ (1,0) [0|0] "" Vector__XXX

BO_ 2583497982 PGN_130316_temperatureExtendedRa: 8 Vector__XXX
 SG_ setTemperature : 48|16@1+ (0.1,0) [0|0] "K" Vector__XXX
 SG_ temperature : 24|24@1+ (0.001,0) [0|0] "K" Vector__XXX
 SG_ source : 16|8@1+ (1,0) [0|0] "" Vector__XXX
 SG_ instance : 8|8@1+ (1,0) [0|0] "" Vector__XXX
 SG_ sid : 0|8@1+ (1,0) [0|0] "" Vector__XXX

BO_ 2583499006 PGN_130320_tideStationData: 8 Vector__XXX
 SG_ fastPacketData : 8|56@1+ (1,0) [0|0] "" Vector__XXX
 SG_ fastPacketSequenceCounter : 0|8@1+ (1,0) [0|0] "" Vector__XXX

BO_ 2583499262 PGN_130321_salinityStationData: 8 Vector__XXX
 SG_ fastPacketData : 8|56@1+ (1,0) [0|0] "" Vector__XXX
 SG_ fastPacketSequenceCounter : 0|8@1+ (1,0) [0|0] "" Vector__XXX

BO_ 2583499518 PGN_130322_currentStationData: 8 Vector__XXX
 SG_ fastPacketData : 8|56@1+ (1,0) [0|0] "" Vector__XXX
 SG_ fastPacketSequenceCounter : 0|8@1+ (1,0) [0|0] "" Vector__XXX

BO_ 2583499774 PGN_130323_meteorologicalStation: 8 Vector__XXX
 SG_ fastPacketData : 8|56@1+ (1,0) [0|0] "" Vector__XXX
 SG_ fastPacketSequenceCounter : 0|8@1+ (1,0) [0|0] "" Vector__XXX

BO_ 2583500030 PGN_130324_mooredBuoyStationData: 8 Vector__XXX
 SG_ fastPacketData : 8|56@1+ (1,0) [0|0] "" Vector__XXX
 SG_ fastPacketSequenceCounter : 0|8@1+ (1,0) [0|0] "" Vector__XXX

BO_ 2583501566 PGN_130330_lightingSystemSetting: 8 Vector__XXX
 SG_ fastPacketData : 8|56@1+ (1,0) [0|0] "" Vector__XXX
 SG_ fastPacketSequenceCounter : 0|8@1+ (1,0) [0|0] "" Vector__XXX

BO_ 2583560446 PGN_130560_payloadMass: 8 Vector__XXX
 SG_ reserved6 : 56|8@1+ (1,0) [0|0] "" Vector__XXX
 SG_ payloadMass : 24|32@1+ (1,0) [0|0] "" Vector__XXX
 SG_ measurementId : 16|8@1+ (1,0) [0|0] "" Vector__XXX
 SG_ reserved : 11|5@1+ (1,0) [0|0] "" Vector__XXX
 SG_ measurementStatus : 8|3@1+ (1,0) [0|0] "" Vector__XXX
 SG_ sid : 0|8@1+ (1,0) [0|0] "" Vector__XXX

BO_ 2583560702 PGN_130561_lightingZone: 8 Vector__XXX
 SG_ fastPacketData : 8|56@1+ (1,0) [0|0] "" Vector__XXX
 SG_ fastPacketSequenceCounter : 0|8@1+ (1,0) [0|0] "" Vector__XXX

BO_ 2583560958 PGN_130562_lightingScene: 8 Vector__XXX
 SG_ fastPacketData : 8|56@1+ (1,0) [0|0] "" Vector__XXX
 SG_ fastPacketSequenceCounter : 0|8@1+ (1,0) [0|0] "" Vector__XXX

BO_ 2583561214 PGN_130563_lightingDevice: 8 Vector__XXX
 SG_ fastPacketData : 8|56@1+ (1,0) [0|0] "" Vector__XXX
 SG_ fastPacketSequenceCounter : 0|8@1+ (1,0) [0|0] "" Vector__XXX

BO_ 2583561470 PGN_130564_lightingDeviceEnumera: 8 Vector__XXX
 SG_ fastPacketData : 8|56@1+ (1,0) [0|0] "" Vector__XXX
 SG_ fastPacketSequenceCounter : 0|8@1+ (1,0) [0|0] "" Vector__XXX

BO_ 2583561726 PGN_130565_lightingColorSequence: 8 Vector__XXX
 SG_ fastPacketData : 8|56@1+ (1,0) [0|0] "" Vector__XXX
 SG_ fastPacketSequenceCounter : 0|8@1+ (1,0) [0|0] "" Vector__XXX

BO_ 2583561982 PGN_130566_lightingProgram: 8 Vector__XXX
 SG_ fastPacketData : 8|56@1+ (1,0) [0|0] "" Vector__XXX
 SG_ fastPacketSequenceCounter : 0|8@1+ (1,0) [0|0] "" Vector__XXX

BO_ 2583562238 PGN_130567_watermakerInputSettin: 8 Vector__XXX
 SG_ fastPacketData : 8|56@1+ (1,0) [0|0] "" Vector__XXX
 SG_ fastPacketSequenceCounter : 0|8@1+ (1,0) [0|0] "" Vector__XXX

BO_ 2583562750 PGN_130569_currentStatusAndFile: 8 Vector__XXX
 SG_ fastPacketData : 8|56@1+ (1,0) [0|0] "" Vector__XXX
 SG_ fastPacketSequenceCounter : 0|8@1+ (1,0) [0|0] "" Vector__XXX

BO_ 2583563006 PGN_130570_libraryDataFile: 8 Vector__XXX
 SG_ fastPacketData : 8|56@1+ (1,0) [0|0] "" Vector__XXX
 SG_ fastPacketSequenceCounter : 0|8@1+ (1,0) [0|0] "" Vector__XXX

BO_ 2583563262 PGN_130571_libraryDataGroup: 8 Vector__XXX
 SG_ fastPacketData : 8|56@1+ (1,0) [0|0] "" Vector__XXX
 SG_ fastPacketSequenceCounter : 0|8@1+ (1,0) [0|0] "" Vector__XXX

BO_ 2583563518 PGN_130572_libraryDataSearch: 8 Vector__XXX
 SG_ fastPacketData : 8|56@1+ (1,0) [0|0] "" Vector__XXX
 SG_ fastPacketSequenceCounter : 0|8@1+ (1,0) [0|0] "" Vector__XXX

BO_ 2583563774 PGN_130573_supportedSourceData: 8 Vector__XXX
 SG_ fastPacketData : 8|56@1+ (1,0) [0|0] "" Vector__XXX
 SG_ fastPacketSequenceCounter : 0|8@1+ (1,0) [0|0] "" Vector__XXX

BO_ 2583564030 PGN_130574_supportedZoneData: 8 Vector__XXX
 SG_ fastPacketData : 8|56@1+ (1,0) [0|0] "" Vector__XXX
 SG_ fastPacketSequenceCounter : 0|8@1+ (1,0) [0|0] "" Vector__XXX

BO_ 2583564542 PGN_130576_smallCraftStatus: 8 Vector__XXX
 SG_ reserved : 16|48@1+ (1,0) [0|0] "" Vector__XXX
 SG_ starboardTrimTab : 8|8@1- (1,0) [0|0] "%" Vector__XXX
 SG_ portTrimTab : 0|8@1- (1,0) [0|0] "%" Vector__XXX

BO_ 2583564798 PGN_130577_directionData: 8 Vector__XXX
 SG_ fastPacketData : 8|56@1+ (1,0) [0|0] "" Vector__XXX
 SG_ fastPacketSequenceCounter : 0|8@1+ (1,0) [0|0] "" Vector__XXX

BO_ 2583565054 PGN_130578_vesselSpeedComponents: 8 Vector__XXX
 SG_ fastPacketData : 8|56@1+ (1,0) [0|0] "" Vector__XXX
 SG_ fastPacketSequenceCounter : 0|8@1+ (1,0) [0|0] "" Vector__XXX

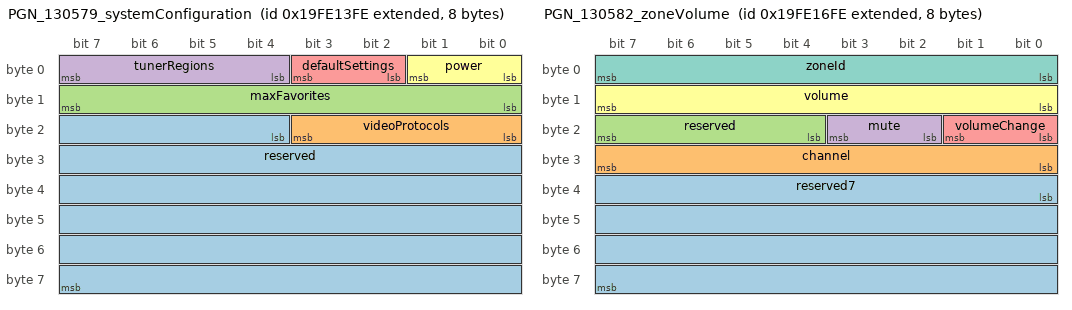
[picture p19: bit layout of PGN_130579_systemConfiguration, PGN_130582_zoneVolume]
BO_ 2583565310 PGN_130579_systemConfiguration: 8 Vector__XXX
 SG_ reserved : 20|44@1+ (1,0) [0|0] "" Vector__XXX
 SG_ videoProtocols : 16|4@1+ (1,0) [0|0] "" Vector__XXX
 SG_ maxFavorites : 8|8@1+ (1,0) [0|0] "" Vector__XXX
 SG_ tunerRegions : 4|4@1+ (1,0) [0|0] "" Vector__XXX
 SG_ defaultSettings : 2|2@1+ (1,0) [0|0] "" Vector__XXX
 SG_ power : 0|2@1+ (1,0) [0|0] "" Vector__XXX

BO_ 2583565566 PGN_130580_systemConfigurationDe: 8 Vector__XXX
 SG_ fastPacketData : 8|56@1+ (1,0) [0|0] "" Vector__XXX
 SG_ fastPacketSequenceCounter : 0|8@1+ (1,0) [0|0] "" Vector__XXX

BO_ 2583565822 PGN_130581_zoneConfigurationDepr: 8 Vector__XXX
 SG_ fastPacketData : 8|56@1+ (1,0) [0|0] "" Vector__XXX
 SG_ fastPacketSequenceCounter : 0|8@1+ (1,0) [0|0] "" Vector__XXX

BO_ 2583566078 PGN_130582_zoneVolume: 8 Vector__XXX
 SG_ reserved7 : 32|32@1+ (1,0) [0|0] "" Vector__XXX
 SG_ channel : 24|8@1+ (1,0) [0|0] "" Vector__XXX
 SG_ reserved : 20|4@1+ (1,0) [0|0] "" Vector__XXX
 SG_ mute : 18|2@1+ (1,0) [0|0] "" Vector__XXX
 SG_ volumeChange : 16|2@1+ (1,0) [0|0] "" Vector__XXX
 SG_ volume : 8|8@1+ (1,0) [0|0] "%" Vector__XXX
 SG_ zoneId : 0|8@1+ (1,0) [0|0] "" Vector__XXX

BO_ 2583566334 PGN_130583_availableAudioEqPrese: 8 Vector__XXX
 SG_ fastPacketData : 8|56@1+ (1,0) [0|0] "" Vector__XXX
 SG_ fastPacketSequenceCounter : 0|8@1+ (1,0) [0|0] "" Vector__XXX

BO_ 2583566590 PGN_130584_availableBluetoothAdd: 8 Vector__XXX
 SG_ fastPacketData : 8|56@1+ (1,0) [0|0] "" Vector__XXX
 SG_ fastPacketSequenceCounter : 0|8@1+ (1,0) [0|0] "" Vector__XXX

BO_ 2583566846 PGN_130585_bluetoothSourceStatus: 8 Vector__XXX
 SG_ bluetoothAddress : 16|48@1+ (1,0) [0|0] "" Vector__XXX
 SG_ discovering : 14|2@1+ (1,0) [0|0] "" Vector__XXX
 SG_ forgetDevice : 12|2@1+ (1,0) [0|0] "" Vector__XXX
 SG_ status : 8|4@1+ (1,0) [0|0] "" Vector__XXX
 SG_ sourceNumber : 0|8@1+ (1,0) [0|0] "" Vector__XXX

BO_ 2583567102 PGN_130586_zoneConfiguration: 8 Vector__XXX
 SG_ fastPacketData : 8|56@1+ (1,0) [0|0] "" Vector__XXX
 SG_ fastPacketSequenceCounter : 0|8@1+ (1,0) [0|0] "" Vector__XXX

BO_ 2583626494 PGN_130818_simnetReprogramData: 8 Vector__XXX
 SG_ fastPacketData : 8|56@1+ (1,0) [0|0] "" Vector__XXX
 SG_ fastPacketSequenceCounter : 0|8@1+ (1,0) [0|0] "" Vector__XXX

BO_ 2583626750 PGN_130819_simnetRequestReprogra: 8 Vector__XXX
 SG_ fastPacketData : 8|56@1+ (1,0) [0|0] "" Vector__XXX
 SG_ fastPacketSequenceCounter : 0|8@1+ (1,0) [0|0] "" Vector__XXX

BO_ 2583627518 PGN_130822_navicoUnknown1: 8 Vector__XXX
 SG_ fastPacketData : 8|56@1+ (1,0) [0|0] "" Vector__XXX
 SG_ fastPacketSequenceCounter : 0|8@1+ (1,0) [0|0] "" Vector__XXX

BO_ 2583627774 PGN_130823_maretronProprietaryTe: 8 Vector__XXX
 SG_ fastPacketData : 8|56@1+ (1,0) [0|0] "" Vector__XXX
 SG_ fastPacketSequenceCounter : 0|8@1+ (1,0) [0|0] "" Vector__XXX

BO_ 2583628286 PGN_130825_navicoUnknown2: 8 Vector__XXX
 SG_ fastPacketData : 8|56@1+ (1,0) [0|0] "" Vector__XXX
 SG_ fastPacketSequenceCounter : 0|8@1+ (1,0) [0|0] "" Vector__XXX

BO_ 2583628798 PGN_130827_lowranceUnknown: 8 Vector__XXX
 SG_ fastPacketData : 8|56@1+ (1,0) [0|0] "" Vector__XXX
 SG_ fastPacketSequenceCounter : 0|8@1+ (1,0) [0|0] "" Vector__XXX

BO_ 2583629054 PGN_130828_simnetSetSerialNumber: 8 Vector__XXX
 SG_ fastPacketData : 8|56@1+ (1,0) [0|0] "" Vector__XXX
 SG_ fastPacketSequenceCounter : 0|8@1+ (1,0) [0|0] "" Vector__XXX

BO_ 2583629822 PGN_130831_suzukiEngineAndStorag: 8 Vector__XXX
 SG_ fastPacketData : 8|56@1+ (1,0) [0|0] "" Vector__XXX
 SG_ fastPacketSequenceCounter : 0|8@1+ (1,0) [0|0] "" Vector__XXX

BO_ 2583630078 PGN_130832_simnetFuelUsedHighRes: 8 Vector__XXX
 SG_ fastPacketData : 8|56@1+ (1,0) [0|0] "" Vector__XXX
 SG_ fastPacketSequenceCounter : 0|8@1+ (1,0) [0|0] "" Vector__XXX

BO_ 2583630334 PGN_130833_bGUserAndRemoteRename: 8 Vector__XXX
 SG_ fastPacketData : 8|56@1+ (1,0) [0|0] "" Vector__XXX
 SG_ fastPacketSequenceCounter : 0|8@1+ (1,0) [0|0] "" Vector__XXX

BO_ 2583630590 PGN_130834_simnetEngineAndTankCo: 8 Vector__XXX
 SG_ fastPacketData : 8|56@1+ (1,0) [0|0] "" Vector__XXX
 SG_ fastPacketSequenceCounter : 0|8@1+ (1,0) [0|0] "" Vector__XXX

BO_ 2583630846 PGN_130835_simnetSetEngineAndTan: 8 Vector__XXX
 SG_ fastPacketData : 8|56@1+ (1,0) [0|0] "" Vector__XXX
 SG_ fastPacketSequenceCounter : 0|8@1+ (1,0) [0|0] "" Vector__XXX

BO_ 2583631614 PGN_130838_simnetFluidLevelWarni: 8 Vector__XXX
 SG_ fastPacketData : 8|56@1+ (1,0) [0|0] "" Vector__XXX
 SG_ fastPacketSequenceCounter : 0|8@1+ (1,0) [0|0] "" Vector__XXX

BO_ 2583631870 PGN_130839_simnetPressureSensorC: 8 Vector__XXX
 SG_ fastPacketData : 8|56@1+ (1,0) [0|0] "" Vector__XXX
 SG_ fastPacketSequenceCounter : 0|8@1+ (1,0) [0|0] "" Vector__XXX

BO_ 2583632126 PGN_130840_simnetDataUserGroupCo: 8 Vector__XXX
 SG_ fastPacketData : 8|56@1+ (1,0) [0|0] "" Vector__XXX
 SG_ fastPacketSequenceCounter : 0|8@1+ (1,0) [0|0] "" Vector__XXX

BO_ 2583633918 PGN_130847_seatalkNodeStatistics: 8 Vector__XXX
 SG_ fastPacketData : 8|56@1+ (1,0) [0|0] "" Vector__XXX
 SG_ fastPacketSequenceCounter : 0|8@1+ (1,0) [0|0] "" Vector__XXX

BO_ 2583634174 PGN_130848_seatalkWaypointInform: 8 Vector__XXX
 SG_ fastPacketData : 8|56@1+ (1,0) [0|0] "" Vector__XXX
 SG_ fastPacketSequenceCounter : 0|8@1+ (1,0) [0|0] "" Vector__XXX

BO_ 2583634942 PGN_130851_simnetEventReplyApCom: 8 Vector__XXX
 SG_ fastPacketData : 8|56@1+ (1,0) [0|0] "" Vector__XXX
 SG_ fastPacketSequenceCounter : 0|8@1+ (1,0) [0|0] "" Vector__XXX

BO_ 2583636222 PGN_130856_simnetAlarmMessage: 8 Vector__XXX
 SG_ fastPacketData : 8|56@1+ (1,0) [0|0] "" Vector__XXX
 SG_ fastPacketSequenceCounter : 0|8@1+ (1,0) [0|0] "" Vector__XXX

BO_ 2583637246 PGN_130860_simnetApUnknown4: 8 Vector__XXX
 SG_ fastPacketData : 8|56@1+ (1,0) [0|0] "" Vector__XXX
 SG_ fastPacketSequenceCounter : 0|8@1+ (1,0) [0|0] "" Vector__XXX

BO_ 2583642366 PGN_130880_airmarAdditionalWeath: 8 Vector__XXX
 SG_ fastPacketData : 8|56@1+ (1,0) [0|0] "" Vector__XXX
 SG_ fastPacketSequenceCounter : 0|8@1+ (1,0) [0|0] "" Vector__XXX

BO_ 2583642622 PGN_130881_airmarHeaterControl: 8 Vector__XXX
 SG_ fastPacketData : 8|56@1+ (1,0) [0|0] "" Vector__XXX
 SG_ fastPacketSequenceCounter : 0|8@1+ (1,0) [0|0] "" Vector__XXX

BO_ 2583652094 PGN_130918_seatalkRouteInformati: 8 Vector__XXX
 SG_ fastPacketData : 8|56@1+ (1,0) [0|0] "" Vector__XXX
 SG_ fastPacketSequenceCounter : 0|8@1+ (1,0) [0|0] "" Vector__XXX

BO_ 2583658750 PGN_130944_airmarPost: 8 Vector__XXX
 SG_ fastPacketData : 8|56@1+ (1,0) [0|0] "" Vector__XXX
 SG_ fastPacketSequenceCounter : 0|8@1+ (1,0) [0|0] "" Vector__XXX

CM_ BO_ 2565341438 "ISO Acknowledgement";
CM_ SG_ 2565341438 pgn "Parameter Group Number of requested information";
CM_ BO_ 2565472510 "ISO Request";
CM_ BO_ 2565538046 "ISO Transport Protocol, Data Transfer";
CM_ SG_ 2565538046 data "Multi-packet packetized data - 56 bits organized as seven 8-bit bytes, each of the bytes is transmitted in the same order as it would in a standard (i.e., single frame) message. Unused bytes shall be filled with 0xFF.";
CM_ SG_ 2565538046 sid "Sequence number of multi-packet frame";
CM_ BO_ 2565734654 "ISO Address Claim";
CM_ SG_ 2565734654 arbitraryAddressCapable "Field indicates whether the device is capable to claim arbitrary source address. Value is 1 for NMEA200 devices. Could be 0 for J1939 device claims";
CM_ SG_ 2565734654 systemInstance "ISO Device Class Instance";
CM_ SG_ 2565734654 deviceFunction "ISO Function";
CM_ SG_ 2565734654 deviceInstanceUpper "ISO Function Instance";
CM_ SG_ 2565734654 deviceInstanceLower "ISO ECU Instance";
CM_ SG_ 2565734654 uniqueNumber "ISO Identity Number";
CM_ BO_ 2566777342 "Bus #1 Phase C Basic AC Quantities";
CM_ BO_ 2566777598 "Bus #1 Phase B Basic AC Quantities";
CM_ BO_ 2566777854 "Bus #1 Phase A Basic AC Quantities";
CM_ BO_ 2566778110 "Bus #1 Average Basic AC Quantities";
CM_ BO_ 2566778366 "Utility Total AC Energy";
CM_ BO_ 2566778622 "Utility Phase C AC Reactive Power";
CM_ BO_ 2566778878 "Utility Phase C AC Power";
CM_ BO_ 2566779134 "Utility Phase C Basic AC Quantities";
CM_ BO_ 2566779390 "Utility Phase B AC Reactive Power";
CM_ BO_ 2566779646 "Utility Phase B AC Power";
CM_ BO_ 2566779902 "Utility Phase B Basic AC Quantities";
CM_ BO_ 2566780158 "Utility Phase A AC Reactive Power";
CM_ BO_ 2566780414 "Utility Phase A AC Power";
CM_ BO_ 2566780670 "Utility Phase A Basic AC Quantities";
CM_ BO_ 2566780926 "Utility Total AC Reactive Power";
CM_ BO_ 2566781182 "Utility Total AC Power";
CM_ BO_ 2566781438 "Utility Average Basic AC Quantities";
CM_ BO_ 2566781694 "Generator Total AC Energy";
CM_ BO_ 2566781950 "Generator Phase C AC Reactive Power";
CM_ BO_ 2566782206 "Generator Phase C AC Power";
CM_ BO_ 2566782462 "Generator Phase C Basic AC Quantities";
CM_ BO_ 2566782718 "Generator Phase B AC Reactive Power";
CM_ BO_ 2566782974 "Generator Phase B AC Power";
CM_ BO_ 2566783230 "Generator Phase B Basic AC Quantities";
CM_ BO_ 2566783486 "Generator Phase A AC Reactive Power";
CM_ BO_ 2566783742 "Generator Phase A AC Power";
CM_ BO_ 2566783998 "Generator Phase A Basic AC Quantities";
CM_ BO_ 2566784254 "Generator Total AC Reactive Power";
CM_ BO_ 2566784510 "Generator Total AC Power";
CM_ BO_ 2566784766 "Generator Average Basic AC Quantities";
CM_ BO_ 2566848766 "Furuno: Heave";
CM_ SG_ 2566848766 industryCode "Marine Industry";
CM_ SG_ 2566848766 manufacturerCode "Furuno";
CM_ BO_ 2566849790 "Maretron: Proprietary DC Breaker Current";
CM_ SG_ 2566849790 industryCode "Marine Industry";
CM_ SG_ 2566849790 manufacturerCode "Maretron";
CM_ BO_ 2566850814 "Seatalk: Alarm";
CM_ SG_ 2566850814 industryCode "Marine Industry";
CM_ SG_ 2566850814 manufacturerCode "Raymarine";
CM_ BO_ 2566851070 "Simnet: Trim Tab Sensor Calibration";
CM_ SG_ 2566851070 industryCode "Marine Industry";
CM_ SG_ 2566851070 manufacturerCode "Simrad";
CM_ BO_ 2566851326 "Simnet: Paddle Wheel Speed Configuration";
CM_ SG_ 2566851326 industryCode "Marine Industry";
CM_ SG_ 2566851326 manufacturerCode "Simrad";
CM_ BO_ 2566851838 "Simnet: Clear Fluid Level Warnings";
CM_ SG_ 2566851838 industryCode "Marine Industry";
CM_ SG_ 2566851838 manufacturerCode "Simrad";
CM_ BO_ 2566854398 "Simnet: AP Unknown 1";
CM_ SG_ 2566854398 industryCode "Marine Industry";
CM_ SG_ 2566854398 manufacturerCode "Simrad";
CM_ BO_ 2566856190 "Navico: Wireless Battery Status";
CM_ SG_ 2566856190 industryCode "Marine Industry";
CM_ SG_ 2566856190 manufacturerCode "Navico";
CM_ BO_ 2566856958 "Navico: Wireless Signal Status";
CM_ SG_ 2566856958 industryCode "Marine Industry";
CM_ SG_ 2566856958 manufacturerCode "Navico";
CM_ BO_ 2566864126 "Simnet: AP Unknown 2";
CM_ SG_ 2566864126 industryCode "Marine Industry";
CM_ SG_ 2566864126 manufacturerCode "Simrad";
CM_ BO_ 2566864382 "Simnet: Autopilot Angle";
CM_ SG_ 2566864382 industryCode "Marine Industry";
CM_ SG_ 2566864382 manufacturerCode "Simrad";
CM_ BO_ 2566865406 "Seatalk: Pilot Wind Datum";
CM_ SG_ 2566865406 industryCode "Marine Industry";
CM_ SG_ 2566865406 manufacturerCode "Raymarine";
CM_ BO_ 2566866686 "Simnet: Magnetic Field";
CM_ BO_ 2566868990 "Seatalk: Pilot Heading";
CM_ SG_ 2566868990 industryCode "Marine Industry";
CM_ SG_ 2566868990 manufacturerCode "Raymarine";
CM_ BO_ 2566869246 "Seatalk: Pilot Locked Heading";
CM_ SG_ 2566869246 industryCode "Marine Industry";
CM_ SG_ 2566869246 manufacturerCode "Raymarine";
CM_ BO_ 2566869502 "Seatalk: Silence Alarm";
CM_ SG_ 2566869502 industryCode "Marine Industry";
CM_ SG_ 2566869502 manufacturerCode "Raymarine";
CM_ BO_ 2566872062 "Seatalk: Keypad Message";
CM_ SG_ 2566872062 industryCode "Marine Industry";
CM_ SG_ 2566872062 manufacturerCode "Raymarine";
CM_ BO_ 2566872830 "SeaTalk: Keypad Heartbeat";
CM_ SG_ 2566872830 industryCode "Marine Industry";
CM_ SG_ 2566872830 manufacturerCode "Raymarine";
CM_ BO_ 2566874110 "Seatalk: Pilot Mode";
CM_ SG_ 2566874110 industryCode "Marine Industry";
CM_ SG_ 2566874110 manufacturerCode "Raymarine";
CM_ BO_ 2566881534 "Airmar: Depth Quality Factor";
CM_ SG_ 2566881534 industryCode "Marine Industry";
CM_ SG_ 2566881534 manufacturerCode "Airmar";
CM_ BO_ 2566881790 "Airmar: Speed Pulse Count";
CM_ SG_ 2566881790 industryCode "Marine Industry";
CM_ SG_ 2566881790 manufacturerCode "Airmar";
CM_ BO_ 2566882046 "Airmar: Device Information";
CM_ SG_ 2566882046 industryCode "Marine Industry";
CM_ SG_ 2566882046 manufacturerCode "Airmar";
CM_ BO_ 2566884606 "Simnet: AP Unknown 3";
CM_ SG_ 2566884606 industryCode "Marine Industry";
CM_ SG_ 2566884606 manufacturerCode "Simrad";
CM_ BO_ 2566899966 "Simnet: Autopilot Mode";
CM_ SG_ 2566899966 industryCode "Marine Industry";
CM_ SG_ 2566899966 manufacturerCode "Simrad";
CM_ BO_ 2582511870 "PGN List (Transmit and Receive)";
CM_ BO_ 2582644734 "Alert";
CM_ BO_ 2582644990 "Alert Response";
CM_ BO_ 2582645246 "Alert Text";
CM_ BO_ 2582645502 "Alert Configuration";
CM_ BO_ 2582645758 "Alert Threshold";
CM_ BO_ 2582646014 "Alert Value";
CM_ BO_ 2582647038 "System Time";
CM_ SG_ 2582647038 time "Seconds since midnight";
CM_ SG_ 2582647038 sid "An upward counting number used to tie releated information together between different PGNs. For example the SID would be used to tie together the COG, SOG and RAIM values to a given position.";
CM_ BO_ 2582647294 "Heartbeat";
CM_ SG_ 2582647294 dataTransmitOffset "Offset in transmit time from time of request command: 0x0 = transmit immediately, 0xFFFF = Do not change offset.";
CM_ BO_ 2582648062 "Product Information";
CM_ BO_ 2582648574 "Configuration Information";
CM_ BO_ 2582708734 "Man Overboard Notification";
CM_ BO_ 2582709758 "Heading/Track control";
CM_ BO_ 2582711806 "Rudder";
CM_ BO_ 2582713086 "Vessel Heading";
CM_ BO_ 2582713342 "Rate of Turn";
CM_ BO_ 2582713598 "Heave";
CM_ BO_ 2582714878 "Attitude";
CM_ BO_ 2582715134 "Magnetic Variation";
CM_ BO_ 2582774014 "Engine Parameters, Rapid Update";
CM_ BO_ 2582774270 "Engine Parameters, Dynamic";
CM_ BO_ 2582774526 "Electric Drive Status, Dynamic";
CM_ BO_ 2582774782 "Electric Energy Storage Status, Dynamic";
CM_ BO_ 2582775294 "Transmission Parameters, Dynamic";
CM_ BO_ 2582775550 "Electric Drive Information";
CM_ BO_ 2582775806 "Electric Energy Storage Information";
CM_ BO_ 2582776062 "Trip Parameters, Vessel";
CM_ BO_ 2582776318 "Trip Parameters, Engine";
CM_ BO_ 2582776574 "Engine Parameters, Static";
CM_ BO_ 2582777086 "Load Controller Connection State/Control";
CM_ BO_ 2582777342 "Binary Switch Bank Status";
CM_ BO_ 2582777598 "Switch Bank Control";
CM_ BO_ 2582777854 "AC Input Status";
CM_ BO_ 2582778110 "AC Output Status";
CM_ BO_ 2582778366 "Fluid Level";
CM_ BO_ 2582778622 "DC Detailed Status";
CM_ BO_ 2582778878 "Charger Status";
CM_ BO_ 2582779134 "Battery Status";
CM_ BO_ 2582779390 "Inverter Status";
CM_ BO_ 2582779646 "Charger Configuration Status";
CM_ BO_ 2582779902 "Inverter Configuration Status";
CM_ BO_ 2582780158 "AGS Configuration Status";
CM_ BO_ 2582780414 "Battery Configuration Status";
CM_ BO_ 2582780670 "AGS Status";
CM_ BO_ 2582839550 "AC Power / Current - Phase A";
CM_ BO_ 2582839806 "AC Power / Current - Phase B";
CM_ BO_ 2582840062 "AC Power / Current - Phase C";
CM_ BO_ 2582840318 "AC Voltage / Frequency - Phase A";
CM_ BO_ 2582840574 "AC Voltage / Frequency - Phase B";
CM_ BO_ 2582840830 "AC Voltage / Frequency - Phase C";
CM_ BO_ 2582841086 "Converter Status";
CM_ BO_ 2582841342 "DC Voltage/Current";
CM_ BO_ 2582905086 "Leeway Angle";
CM_ BO_ 2582905342 "Vessel Acceleration";
CM_ BO_ 2582905598 "Electric Drive Status, Rapid Update";
CM_ BO_ 2582905854 "Electric Energy Storage Status, Rapid Update";
CM_ BO_ 2582906622 "Thruster Control Status";
CM_ BO_ 2582906878 "Thruster Information";
CM_ BO_ 2582907134 "Thruster Motor Status";
CM_ BO_ 2582971390 "Speed";
CM_ BO_ 2582973438 "Water Depth";
CM_ SG_ 2582973438 range "Max measurement range";
CM_ SG_ 2582973438 offset "Distance between transducer and surface (positive) or keel (negative)";
CM_ SG_ 2582973438 depth "Depth below transducer";
CM_ BO_ 2582975486 "Distance Log";
CM_ BO_ 2583038206 "Tracked Target Data";
CM_ BO_ 2583042814 "Elevator Car Status";
CM_ BO_ 2583101694 "Elevator Motor Control";
CM_ BO_ 2583101950 "Elevator Deck Push Button";
CM_ BO_ 2583103742 "Windlass Control Status";
CM_ SG_ 2583103742 commandTimeout "If timeout elapses the thruster stops operating and reverts to static mode";
CM_ SG_ 2583103742 speedControl "0=Off,Single speed:1-100=On,Dual Speed:1-49=Slow/50-100=Fast,Proportional:10-100";
CM_ BO_ 2583103998 "Anchor Windlass Operating Status";
CM_ BO_ 2583104254 "Anchor Windlass Monitoring Status";
CM_ BO_ 2583104766 "Linear Actuator Control/Status";
CM_ BO_ 2583167486 "Position, Rapid Update";
CM_ BO_ 2583167742 "COG & SOG, Rapid Update";
CM_ BO_ 2583167998 "Position Delta, Rapid Update";
CM_ BO_ 2583168254 "Altitude Delta, Rapid Update";
CM_ BO_ 2583168510 "GNSS Position Data";
CM_ BO_ 2583169534 "Time & Date";
CM_ SG_ 2583169534 time "Seconds since midnight";
CM_ BO_ 2583170814 "AIS Class A Position Report";
CM_ BO_ 2583171070 "AIS Class B Position Report";
CM_ BO_ 2583171326 "AIS Class B Extended Position Report";
CM_ BO_ 2583171582 "AIS Aids to Navigation (AtoN) Report";
CM_ BO_ 2583172350 "Datum";
CM_ BO_ 2583172606 "User Datum";
CM_ BO_ 2583233534 "Cross Track Error";
CM_ BO_ 2583233790 "Navigation Data";
CM_ BO_ 2583234046 "Navigation - Route/WP Information";
CM_ BO_ 2583235582 "Set & Drift, Rapid Update";
CM_ BO_ 2583238142 "Navigation - Route / Time to+from Mark";
CM_ BO_ 2583238398 "Bearing and Distance between two Marks";
CM_ BO_ 2583298814 "GNSS Control Status";
CM_ BO_ 2583299070 "GNSS DOPs";
CM_ SG_ 2583299070 tdop "Time dilution of precision";
CM_ SG_ 2583299070 vdop "Vertical dilution of precision";
CM_ SG_ 2583299070 hdop "Horizontal dilution of precision";
CM_ BO_ 2583299326 "GNSS Sats in View";
CM_ BO_ 2583299582 "GPS Almanac Data";
CM_ BO_ 2583299838 "GNSS Pseudorange Noise Statistics";
CM_ BO_ 2583300606 "GNSS RAIM Output";
CM_ BO_ 2583300862 "GNSS RAIM Settings";
CM_ BO_ 2583301118 "GNSS Pseudorange Error Statistics";
CM_ BO_ 2583301630 "DGNSS Corrections";
CM_ BO_ 2583301886 "GNSS Differential Correction Receiver Interface";
CM_ BO_ 2583302142 "GNSS Differential Correction Receiver Signal";
CM_ BO_ 2583303422 "GLONASS Almanac Data";
CM_ BO_ 2583363838 "AIS DGNSS Broadcast Binary Message";
CM_ BO_ 2583364094 "AIS UTC and Date Report";
CM_ BO_ 2583364350 "AIS Class A Static and Voyage Related Data";
CM_ BO_ 2583364606 "AIS Addressed Binary Message";
CM_ BO_ 2583364862 "AIS Acknowledge";
CM_ BO_ 2583365118 "AIS Binary Broadcast Message";
CM_ BO_ 2583365374 "AIS SAR Aircraft Position Report";
CM_ BO_ 2583365630 "Radio Frequency/Mode/Power";
CM_ BO_ 2583365886 "AIS UTC/Date Inquiry";
CM_ BO_ 2583366142 "AIS Addressed Safety Related Message";
CM_ BO_ 2583366398 "AIS Safety Related Broadcast Message";
CM_ BO_ 2583366654 "AIS Interrogation";
CM_ BO_ 2583366910 "AIS Assignment Mode Command";
CM_ BO_ 2583367166 "AIS Data Link Management Message";
CM_ BO_ 2583367422 "AIS Channel Management";
CM_ BO_ 2583367678 "AIS Class B Group Assignment";
CM_ BO_ 2583368190 "AIS Class B static data (msg 24 Part A)";
CM_ BO_ 2583368446 "AIS Class B static data (msg 24 Part B)";
CM_ BO_ 2583430398 "Loran-C TD Data";
CM_ BO_ 2583430654 "Loran-C Range Data";
CM_ BO_ 2583430910 "Loran-C Signal Data";
CM_ BO_ 2583432446 "Label";
CM_ BO_ 2583432702 "Channel Source Configuration";
CM_ BO_ 2583433470 "Route and WP Service - Database List";
CM_ BO_ 2583433726 "Route and WP Service - Route List";
CM_ BO_ 2583433982 "Route and WP Service - Route/WP-List Attributes";
CM_ BO_ 2583434238 "Route and WP Service - Route - WP Name & Position";
CM_ BO_ 2583434494 "Route and WP Service - Route - WP Name";
CM_ BO_ 2583434750 "Route and WP Service - XTE Limit & Navigation Method";
CM_ BO_ 2583435006 "Route and WP Service - WP Comment";
CM_ BO_ 2583435262 "Route and WP Service - Route Comment";
CM_ BO_ 2583435518 "Route and WP Service - Database Comment";
CM_ BO_ 2583435774 "Route and WP Service - Radius of Turn";
CM_ BO_ 2583436030 "Route and WP Service - WP List - WP Name & Position";
CM_ BO_ 2583495422 "Wind Data";
CM_ BO_ 2583496446 "Environmental Parameters (obsolete)";
CM_ BO_ 2583496702 "Environmental Parameters";
CM_ BO_ 2583496958 "Temperature";
CM_ BO_ 2583497214 "Humidity";
CM_ BO_ 2583497470 "Actual Pressure";
CM_ BO_ 2583497726 "Set Pressure";
CM_ BO_ 2583497982 "Temperature Extended Range";
CM_ BO_ 2583499006 "Tide Station Data";
CM_ BO_ 2583499262 "Salinity Station Data";
CM_ BO_ 2583499518 "Current Station Data";
CM_ BO_ 2583499774 "Meteorological Station Data";
CM_ BO_ 2583500030 "Moored Buoy Station Data";
CM_ BO_ 2583501566 "Lighting System Settings";
CM_ BO_ 2583560446 "Payload Mass";
CM_ BO_ 2583560702 "Lighting Zone";
CM_ BO_ 2583560958 "Lighting Scene";
CM_ BO_ 2583561214 "Lighting Device";
CM_ BO_ 2583561470 "Lighting Device Enumeration";
CM_ BO_ 2583561726 "Lighting Color Sequence";
CM_ BO_ 2583561982 "Lighting Program";
CM_ BO_ 2583562238 "Watermaker Input Setting and Status";
CM_ BO_ 2583562750 "Current Status and File";
CM_ BO_ 2583563006 "Library Data File";
CM_ BO_ 2583563262 "Library Data Group";
CM_ BO_ 2583563518 "Library Data Search";
CM_ BO_ 2583563774 "Supported Source Data";
CM_ BO_ 2583564030 "Supported Zone Data";
CM_ BO_ 2583564542 "Small Craft Status";
CM_ BO_ 2583564798 "Direction Data";
CM_ BO_ 2583565054 "Vessel Speed Components";
CM_ BO_ 2583565310 "System Configuration";
CM_ BO_ 2583565566 "System Configuration (deprecated)";
CM_ BO_ 2583565822 "Zone Configuration (deprecated)";
CM_ BO_ 2583566078 "Zone Volume";
CM_ SG_ 2583566078 volumeChange "Write only";
CM_ BO_ 2583566334 "Available Audio EQ presets";
CM_ BO_ 2583566590 "Available Bluetooth addresses";
CM_ BO_ 2583566846 "Bluetooth source status";
CM_ BO_ 2583567102 "Zone Configuration";
CM_ BO_ 2583626494 "Simnet: Reprogram Data";
CM_ BO_ 2583626750 "Simnet: Request Reprogram";
CM_ BO_ 2583627518 "Navico: Unknown 1";
CM_ BO_ 2583627774 "Maretron: Proprietary Temperature High Range";
CM_ BO_ 2583628286 "Navico: Unknown 2";
CM_ BO_ 2583628798 "Lowrance: unknown";
CM_ BO_ 2583629054 "Simnet: Set Serial Number";
CM_ BO_ 2583629822 "Suzuki: Engine and Storage Device Config";
CM_ BO_ 2583630078 "Simnet: Fuel Used - High Resolution";
CM_ BO_ 2583630334 "B&G: User and Remote rename";
CM_ BO_ 2583630590 "Simnet: Engine and Tank Configuration";
CM_ BO_ 2583630846 "Simnet: Set Engine and Tank Configuration";
CM_ BO_ 2583631614 "Simnet: Fluid Level Warning";
CM_ BO_ 2583631870 "Simnet: Pressure Sensor Configuration";
CM_ BO_ 2583632126 "Simnet: Data User Group Configuration";
CM_ BO_ 2583633918 "SeaTalk: Node Statistics";
CM_ BO_ 2583634174 "SeaTalk: Waypoint Information";
CM_ BO_ 2583634942 "Simnet: Event Reply: AP command";
CM_ BO_ 2583636222 "Simnet: Alarm Message";
CM_ BO_ 2583637246 "Simnet: AP Unknown 4";
CM_ BO_ 2583642366 "Airmar: Additional Weather Data";
CM_ BO_ 2583642622 "Airmar: Heater Control";
CM_ BO_ 2583652094 "SeaTalk: Route Information";
CM_ BO_ 2583658750 "Airmar: POST";
BA_DEF_ BO_  "SystemMessageLongSymbol" STRING ;
BA_DEF_ SG_  "SystemSignalLongSymbol" STRING ;
BA_DEF_DEF_  "SystemMessageLongSymbol" "";
BA_DEF_DEF_  "SystemSignalLongSymbol" "";
BA_ "SystemMessageLongSymbol" BO_ 2565538046 "PGN_60160_isoTransportProtocolDataTransfer";
BA_ "SystemMessageLongSymbol" BO_ 2566777342 "PGN_65001_bus1PhaseCBasicAcQuantities";
BA_ "SystemMessageLongSymbol" BO_ 2566777598 "PGN_65002_bus1PhaseBBasicAcQuantities";
BA_ "SystemMessageLongSymbol" BO_ 2566777854 "PGN_65003_bus1PhaseABasicAcQuantities";
BA_ "SystemMessageLongSymbol" BO_ 2566778110 "PGN_65004_bus1AverageBasicAcQuantities";
BA_ "SystemMessageLongSymbol" BO_ 2566778622 "PGN_65006_utilityPhaseCAcReactivePower";
BA_ "SystemMessageLongSymbol" BO_ 2566779134 "PGN_65008_utilityPhaseCBasicAcQuantities";
BA_ "SystemMessageLongSymbol" BO_ 2566779390 "PGN_65009_utilityPhaseBAcReactivePower";
BA_ "SystemMessageLongSymbol" BO_ 2566779902 "PGN_65011_utilityPhaseBBasicAcQuantities";
BA_ "SystemMessageLongSymbol" BO_ 2566780158 "PGN_65012_utilityPhaseAAcReactivePower";
BA_ "SystemMessageLongSymbol" BO_ 2566780670 "PGN_65014_utilityPhaseABasicAcQuantities";
BA_ "SystemMessageLongSymbol" BO_ 2566780926 "PGN_65015_utilityTotalAcReactivePower";
BA_ "SystemMessageLongSymbol" BO_ 2566781438 "PGN_65017_utilityAverageBasicAcQuantities";
BA_ "SystemMessageLongSymbol" BO_ 2566781950 "PGN_65019_generatorPhaseCAcReactivePower";
BA_ "SystemMessageLongSymbol" BO_ 2566782462 "PGN_65021_generatorPhaseCBasicAcQuantities";
BA_ "SystemMessageLongSymbol" BO_ 2566782718 "PGN_65022_generatorPhaseBAcReactivePower";
BA_ "SystemMessageLongSymbol" BO_ 2566783230 "PGN_65024_generatorPhaseBBasicAcQuantities";
BA_ "SystemMessageLongSymbol" BO_ 2566783486 "PGN_65025_generatorPhaseAAcReactivePower";
BA_ "SystemMessageLongSymbol" BO_ 2566783998 "PGN_65027_generatorPhaseABasicAcQuantities";
BA_ "SystemMessageLongSymbol" BO_ 2566784254 "PGN_65028_generatorTotalAcReactivePower";
BA_ "SystemMessageLongSymbol" BO_ 2566784766 "PGN_65030_generatorAverageBasicAcQuantities";
BA_ "SystemMessageLongSymbol" BO_ 2566849790 "PGN_65284_maretronProprietaryDcBreakerCurrent";
BA_ "SystemMessageLongSymbol" BO_ 2566851070 "PGN_65289_simnetTrimTabSensorCalibration";
BA_ "SystemMessageLongSymbol" BO_ 2566851326 "PGN_65290_simnetPaddleWheelSpeedConfiguration";
BA_ "SystemMessageLongSymbol" BO_ 2566851838 "PGN_65292_simnetClearFluidLevelWarnings";
BA_ "SystemMessageLongSymbol" BO_ 2566856190 "PGN_65309_navicoWirelessBatteryStatus";
BA_ "SystemMessageLongSymbol" BO_ 2566856958 "PGN_65312_navicoWirelessSignalStatus";
BA_ "SystemMessageLongSymbol" BO_ 2566869246 "PGN_65360_seatalkPilotLockedHeading";
BA_ "SystemMessageLongSymbol" BO_ 2566881534 "PGN_65408_airmarDepthQualityFactor";
BA_ "SystemMessageLongSymbol" BO_ 2566882046 "PGN_65410_airmarDeviceInformation";
BA_ "SystemMessageLongSymbol" BO_ 2582511870 "PGN_126464_pgnListTransmitAndReceive";
BA_ "SystemMessageLongSymbol" BO_ 2582648574 "PGN_126998_configurationInformation";
BA_ "SystemMessageLongSymbol" BO_ 2582708734 "PGN_127233_manOverboardNotification";
BA_ "SystemMessageLongSymbol" BO_ 2582774014 "PGN_127488_engineParametersRapidUpdate";
BA_ "SystemMessageLongSymbol" BO_ 2582774270 "PGN_127489_engineParametersDynamic";
BA_ "SystemMessageLongSymbol" BO_ 2582774526 "PGN_127490_electricDriveStatusDynamic";
BA_ "SystemMessageLongSymbol" BO_ 2582774782 "PGN_127491_electricEnergyStorageStatusDynamic";
BA_ "SystemMessageLongSymbol" BO_ 2582775294 "PGN_127493_transmissionParametersDynamic";
BA_ "SystemMessageLongSymbol" BO_ 2582775550 "PGN_127494_electricDriveInformation";
BA_ "SystemMessageLongSymbol" BO_ 2582775806 "PGN_127495_electricEnergyStorageInformation";
BA_ "SystemMessageLongSymbol" BO_ 2582776574 "PGN_127498_engineParametersStatic";
BA_ "SystemMessageLongSymbol" BO_ 2582777086 "PGN_127500_loadControllerConnectionStateControl";
BA_ "SystemMessageLongSymbol" BO_ 2582777342 "PGN_127501_binarySwitchBankStatus";
BA_ "SystemMessageLongSymbol" BO_ 2582779646 "PGN_127510_chargerConfigurationStatus";
BA_ "SystemMessageLongSymbol" BO_ 2582779902 "PGN_127511_inverterConfigurationStatus";
BA_ "SystemMessageLongSymbol" BO_ 2582780158 "PGN_127512_agsConfigurationStatus";
BA_ "SystemMessageLongSymbol" BO_ 2582780414 "PGN_127513_batteryConfigurationStatus";
BA_ "SystemMessageLongSymbol" BO_ 2582840318 "PGN_127747_acVoltageFrequencyPhaseA";
BA_ "SystemMessageLongSymbol" BO_ 2582840574 "PGN_127748_acVoltageFrequencyPhaseB";
BA_ "SystemMessageLongSymbol" BO_ 2582840830 "PGN_127749_acVoltageFrequencyPhaseC";
BA_ "SystemMessageLongSymbol" BO_ 2582905598 "PGN_128002_electricDriveStatusRapidUpdate";
BA_ "SystemMessageLongSymbol" BO_ 2582905854 "PGN_128003_electricEnergyStorageStatusRapidUpdate";
BA_ "SystemSignalLongSymbol" SG_ 2583101694 motorAccelerationDecelerationPro "motorAccelerationDecelerationProfileSelection";
BA_ "SystemMessageLongSymbol" BO_ 2583101950 "PGN_128769_elevatorDeckPushButton";
BA_ "SystemMessageLongSymbol" BO_ 2583103998 "PGN_128777_anchorWindlassOperatingStatus";
BA_ "SystemMessageLongSymbol" BO_ 2583104254 "PGN_128778_anchorWindlassMonitoringStatus";
BA_ "SystemMessageLongSymbol" BO_ 2583104766 "PGN_128780_linearActuatorControlStatus";
BA_ "SystemMessageLongSymbol" BO_ 2583167998 "PGN_129027_positionDeltaRapidUpdate";
BA_ "SystemMessageLongSymbol" BO_ 2583168254 "PGN_129028_altitudeDeltaRapidUpdate";
BA_ "SystemMessageLongSymbol" BO_ 2583170814 "PGN_129038_aisClassAPositionReport";
BA_ "SystemMessageLongSymbol" BO_ 2583171070 "PGN_129039_aisClassBPositionReport";
BA_ "SystemMessageLongSymbol" BO_ 2583171326 "PGN_129040_aisClassBExtendedPositionReport";
BA_ "SystemMessageLongSymbol" BO_ 2583171582 "PGN_129041_aisAidsToNavigationAtonReport";
BA_ "SystemMessageLongSymbol" BO_ 2583234046 "PGN_129285_navigationRouteWpInformation";
BA_ "SystemMessageLongSymbol" BO_ 2583238142 "PGN_129301_navigationRouteTimeToFromMark";
BA_ "SystemMessageLongSymbol" BO_ 2583238398 "PGN_129302_bearingAndDistanceBetweenTwoMarks";
BA_ "SystemMessageLongSymbol" BO_ 2583299838 "PGN_129542_gnssPseudorangeNoiseStatistics";
BA_ "SystemSignalLongSymbol" SG_ 2583300862 pseudorangeResidualFilteringTime "pseudorangeResidualFilteringTimeConstant";
BA_ "SystemSignalLongSymbol" SG_ 2583300862 radialPositionErrorMaximumThresh "radialPositionErrorMaximumThreshold";
BA_ "SystemMessageLongSymbol" BO_ 2583301118 "PGN_129547_gnssPseudorangeErrorStatistics";
BA_ "SystemMessageLongSymbol" BO_ 2583301886 "PGN_129550_gnssDifferentialCorrectionReceiverInterface";
BA_ "SystemMessageLongSymbol" BO_ 2583302142 "PGN_129551_gnssDifferentialCorrectionReceiverSignal";
BA_ "SystemMessageLongSymbol" BO_ 2583363838 "PGN_129792_aisDgnssBroadcastBinaryMessage";
BA_ "SystemMessageLongSymbol" BO_ 2583364350 "PGN_129794_aisClassAStaticAndVoyageRelatedData";
BA_ "SystemMessageLongSymbol" BO_ 2583364606 "PGN_129795_aisAddressedBinaryMessage";
BA_ "SystemMessageLongSymbol" BO_ 2583365118 "PGN_129797_aisBinaryBroadcastMessage";
BA_ "SystemMessageLongSymbol" BO_ 2583365374 "PGN_129798_aisSarAircraftPositionReport";
BA_ "SystemMessageLongSymbol" BO_ 2583365630 "PGN_129799_radioFrequencyModePower";
BA_ "SystemMessageLongSymbol" BO_ 2583366142 "PGN_129801_aisAddressedSafetyRelatedMessage";
BA_ "SystemMessageLongSymbol" BO_ 2583366398 "PGN_129802_aisSafetyRelatedBroadcastMessage";
BA_ "SystemMessageLongSymbol" BO_ 2583366910 "PGN_129804_aisAssignmentModeCommand";
BA_ "SystemMessageLongSymbol" BO_ 2583367166 "PGN_129805_aisDataLinkManagementMessage";
BA_ "SystemMessageLongSymbol" BO_ 2583367678 "PGN_129807_aisClassBGroupAssignment";
BA_ "SystemMessageLongSymbol" BO_ 2583368190 "PGN_129809_aisClassBStaticDataMsg24PartA";
BA_ "SystemMessageLongSymbol" BO_ 2583368446 "PGN_129810_aisClassBStaticDataMsg24PartB";
BA_ "SystemMessageLongSymbol" BO_ 2583432702 "PGN_130061_channelSourceConfiguration";
BA_ "SystemMessageLongSymbol" BO_ 2583433470 "PGN_130064_routeAndWpServiceDatabaseList";
BA_ "SystemMessageLongSymbol" BO_ 2583433726 "PGN_130065_routeAndWpServiceRouteList";
BA_ "SystemMessageLongSymbol" BO_ 2583433982 "PGN_130066_routeAndWpServiceRouteWpListAttributes";
BA_ "SystemMessageLongSymbol" BO_ 2583434238 "PGN_130067_routeAndWpServiceRouteWpNamePosition";
BA_ "SystemMessageLongSymbol" BO_ 2583434494 "PGN_130068_routeAndWpServiceRouteWpName";
BA_ "SystemMessageLongSymbol" BO_ 2583434750 "PGN_130069_routeAndWpServiceXteLimitNavigationMethod";
BA_ "SystemMessageLongSymbol" BO_ 2583435006 "PGN_130070_routeAndWpServiceWpComment";
BA_ "SystemMessageLongSymbol" BO_ 2583435262 "PGN_130071_routeAndWpServiceRouteComment";
BA_ "SystemMessageLongSymbol" BO_ 2583435518 "PGN_130072_routeAndWpServiceDatabaseComment";
BA_ "SystemMessageLongSymbol" BO_ 2583435774 "PGN_130073_routeAndWpServiceRadiusOfTurn";
BA_ "SystemMessageLongSymbol" BO_ 2583436030 "PGN_130074_routeAndWpServiceWpListWpNamePosition";
BA_ "SystemMessageLongSymbol" BO_ 2583496446 "PGN_130310_environmentalParametersObsolete";
BA_ "SystemMessageLongSymbol" BO_ 2583496702 "PGN_130311_environmentalParameters";
BA_ "SystemMessageLongSymbol" BO_ 2583497982 "PGN_130316_temperatureExtendedRange";
BA_ "SystemMessageLongSymbol" BO_ 2583499774 "PGN_130323_meteorologicalStationData";
BA_ "SystemMessageLongSymbol" BO_ 2583501566 "PGN_130330_lightingSystemSettings";
BA_ "SystemMessageLongSymbol" BO_ 2583561470 "PGN_130564_lightingDeviceEnumeration";
BA_ "SystemMessageLongSymbol" BO_ 2583562238 "PGN_130567_watermakerInputSettingAndStatus";
BA_ "SystemMessageLongSymbol" BO_ 2583565566 "PGN_130580_systemConfigurationDeprecated";
BA_ "SystemMessageLongSymbol" BO_ 2583565822 "PGN_130581_zoneConfigurationDeprecated";
BA_ "SystemMessageLongSymbol" BO_ 2583566334 "PGN_130583_availableAudioEqPresets";
BA_ "SystemMessageLongSymbol" BO_ 2583566590 "PGN_130584_availableBluetoothAddresses";
BA_ "SystemMessageLongSymbol" BO_ 2583626750 "PGN_130819_simnetRequestReprogram";
BA_ "SystemMessageLongSymbol" BO_ 2583627774 "PGN_130823_maretronProprietaryTemperatureHighRange";
BA_ "SystemMessageLongSymbol" BO_ 2583629822 "PGN_130831_suzukiEngineAndStorageDeviceConfig";
BA_ "SystemMessageLongSymbol" BO_ 2583630078 "PGN_130832_simnetFuelUsedHighResolution";
BA_ "SystemMessageLongSymbol" BO_ 2583630590 "PGN_130834_simnetEngineAndTankConfiguration";
BA_ "SystemMessageLongSymbol" BO_ 2583630846 "PGN_130835_simnetSetEngineAndTankConfiguration";
BA_ "SystemMessageLongSymbol" BO_ 2583631614 "PGN_130838_simnetFluidLevelWarning";
BA_ "SystemMessageLongSymbol" BO_ 2583631870 "PGN_130839_simnetPressureSensorConfiguration";
BA_ "SystemMessageLongSymbol" BO_ 2583632126 "PGN_130840_simnetDataUserGroupConfiguration";
BA_ "SystemMessageLongSymbol" BO_ 2583634174 "PGN_130848_seatalkWaypointInformation";
BA_ "SystemMessageLongSymbol" BO_ 2583634942 "PGN_130851_simnetEventReplyApCommand";
BA_ "SystemMessageLongSymbol" BO_ 2583642366 "PGN_130880_airmarAdditionalWeatherData";
BA_ "SystemMessageLongSymbol" BO_ 2583652094 "PGN_130918_seatalkRouteInformation";
VAL_ 2565341438 control 0 "ACK" 1 "NAK" 2 "Access Denied" 3 "Address Busy" ;
VAL_ 2565734654 arbitraryAddressCapable 0 "No" 1 "Yes" ;
VAL_ 2565734654 industryGroup 0 "Global" 1 "Highway" 2 "Agriculture" 3 "Construction" 4 "Marine" 5 "Industrial" ;
VAL_ 2565734654 deviceClass 0 "Reserved for 2000 Use" 10 "System tools" 20 "Safety systems" 25 "Internetwork device" 30 "Electrical Distribution" 35 "Electrical Generation" 40 "Steering and Control surfaces" 50 "Propulsion" 60 "Navigation" 70 "Communication" 75 "Sensor Communication Interface" 80 "Instrumentation/general systems" 85 "External Environment" 90 "Internal Environment" 100 "Deck + cargo + fishing equipment systems" 110 "Human Interface" 120 "Display" 125 "Entertainment" ;
VAL_ 2566778622 powerFactorLagging 0 "Leading" 1 "Lagging" 2 "Error" ;
VAL_ 2566779390 powerFactorLagging 0 "Leading" 1 "Lagging" 2 "Error" ;
VAL_ 2566780158 powerFactorLagging 0 "Leading" 1 "Lagging" 2 "Error" ;
VAL_ 2566780926 powerFactorLagging 0 "Leading" 1 "Lagging" 2 "Error" ;
VAL_ 2566781950 powerFactorLagging 0 "Leading" 1 "Lagging" 2 "Error" ;
VAL_ 2566782718 powerFactorLagging 0 "Leading" 1 "Lagging" 2 "Error" ;
VAL_ 2566783486 powerFactorLagging 0 "Leading" 1 "Lagging" 2 "Error" ;
VAL_ 2566784254 powerFactorLagging 0 "Leading" 1 "Lagging" 2 "Error" ;
VAL_ 2566850814 alarmGroup 0 "Instrument" 1 "Autopilot" 2 "Radar" 3 "Chart Plotter" 4 "AIS" ;
VAL_ 2566850814 alarmId 0 "No Alarm" 1 "Shallow Depth" 2 "Deep Depth" 3 "Shallow Anchor" 4 "Deep Anchor" 5 "Off Course" 6 "AWA High" 7 "AWA Low" 8 "AWS High" 9 "AWS Low" 10 "TWA High" 11 "TWA Low" 12 "TWS High" 13 "TWS Low" 14 "WP Arrival" 15 "Boat Speed High" 16 "Boat Speed Low" 17 "Sea Temperature High" 18 "Sea Temperature Low" 19 "Pilot Watch" 20 "Pilot Off Course" 21 "Pilot Wind Shift" 22 "Pilot Low Battery" 23 "Pilot Last Minute Of Watch" 24 "Pilot No NMEA Data" 25 "Pilot Large XTE" 26 "Pilot NMEA DataError" 27 "Pilot CU Disconnected" 28 "Pilot Auto Release" 29 "Pilot Way Point Advance" 30 "Pilot Drive Stopped" 31 "Pilot Type Unspecified" 32 "Pilot Calibration Required" 33 "Pilot Last Heading" 34 "Pilot No Pilot" 35 "Pilot Route Complete" 36 "Pilot Variable Text" 37 "GPS Failure" 38 "MOB" 39 "Seatalk1 Anchor" 40 "Pilot Swapped Motor Power" 41 "Pilot Standby Too Fast To Fish" 42 "Pilot No GPS Fix" 43 "Pilot No GPS COG" 44 "Pilot Start Up" 45 "Pilot Too Slow" 46 "Pilot No Compass" 47 "Pilot Rate Gyro Fault" 48 "Pilot Current Limit" 49 "Pilot Way Point Advance Port" 50 "Pilot Way Point Advance Stbd" 51 "Pilot No Wind Data" 52 "Pilot No Speed Data" 53 "Pilot Seatalk Fail1" 54 "Pilot Seatalk Fail2" 55 "Pilot Warning Too Fast To Fish" 56 "Pilot Auto Dockside Fail" 57 "Pilot Turn Too Fast" 58 "Pilot No Nav Data" 59 "Pilot Lost Waypoint Data" 60 "Pilot EEPROM Corrupt" 61 "Pilot Rudder Feedback Fail" 62 "Pilot Autolearn Fail1" 63 "Pilot Autolearn Fail2" 64 "Pilot Autolearn Fail3" 65 "Pilot Autolearn Fail4" 66 "Pilot Autolearn Fail5" 67 "Pilot Autolearn Fail6" 68 "Pilot Warning Cal Required" 69 "Pilot Warning OffCourse" 70 "Pilot Warning XTE" 71 "Pilot Warning Wind Shift" 72 "Pilot Warning Drive Short" 73 "Pilot Warning Clutch Short" 74 "Pilot Warning Solenoid Short" 75 "Pilot Joystick Fault" 76 "Pilot No Joystick Data" 80 "Pilot Invalid Command" 81 "AIS TX Malfunction" 82 "AIS Antenna VSWR fault" 83 "AIS Rx channel 1 malfunction" 84 "AIS Rx channel 2 malfunction" 85 "AIS No sensor position in use" 86 "AIS No valid SOG information" 87 "AIS No valid COG information" 88 "AIS 12V alarm" 89 "AIS 6V alarm" 90 "AIS Noise threshold exceeded channel A" 91 "AIS Noise threshold exceeded channel B" 92 "AIS Transmitter PA fault" 93 "AIS 3V3 alarm" 94 "AIS Rx channel 70 malfunction" 95 "AIS Heading lost/invalid" 96 "AIS internal GPS lost" 97 "AIS No sensor position" 98 "AIS Lock failure" 99 "AIS Internal GGA timeout" 100 "AIS Protocol stack restart" 101 "Pilot No IPS communications" 102 "Pilot Power-On or Sleep-Switch Reset While Engaged" 103 "Pilot Unexpected Reset While Engaged" 104 "AIS Dangerous Target" 105 "AIS Lost Target" 106 "AIS Safety Related Message (used to silence)" 107 "AIS Connection Lost" 108 "No Fix" ;
VAL_ 2566850814 alarmStatus 0 "Alarm condition not met" 1 "Alarm condition met and not silenced" 2 "Alarm condition met and silenced" ;
VAL_ 2566864382 mode 2 "Heading" 3 "Wind" 10 "Nav" 11 "No Drift" ;
VAL_ 2566869502 alarmGroup 0 "Instrument" 1 "Autopilot" 2 "Radar" 3 "Chart Plotter" 4 "AIS" ;
VAL_ 2566869502 alarmId 0 "No Alarm" 1 "Shallow Depth" 2 "Deep Depth" 3 "Shallow Anchor" 4 "Deep Anchor" 5 "Off Course" 6 "AWA High" 7 "AWA Low" 8 "AWS High" 9 "AWS Low" 10 "TWA High" 11 "TWA Low" 12 "TWS High" 13 "TWS Low" 14 "WP Arrival" 15 "Boat Speed High" 16 "Boat Speed Low" 17 "Sea Temperature High" 18 "Sea Temperature Low" 19 "Pilot Watch" 20 "Pilot Off Course" 21 "Pilot Wind Shift" 22 "Pilot Low Battery" 23 "Pilot Last Minute Of Watch" 24 "Pilot No NMEA Data" 25 "Pilot Large XTE" 26 "Pilot NMEA DataError" 27 "Pilot CU Disconnected" 28 "Pilot Auto Release" 29 "Pilot Way Point Advance" 30 "Pilot Drive Stopped" 31 "Pilot Type Unspecified" 32 "Pilot Calibration Required" 33 "Pilot Last Heading" 34 "Pilot No Pilot" 35 "Pilot Route Complete" 36 "Pilot Variable Text" 37 "GPS Failure" 38 "MOB" 39 "Seatalk1 Anchor" 40 "Pilot Swapped Motor Power" 41 "Pilot Standby Too Fast To Fish" 42 "Pilot No GPS Fix" 43 "Pilot No GPS COG" 44 "Pilot Start Up" 45 "Pilot Too Slow" 46 "Pilot No Compass" 47 "Pilot Rate Gyro Fault" 48 "Pilot Current Limit" 49 "Pilot Way Point Advance Port" 50 "Pilot Way Point Advance Stbd" 51 "Pilot No Wind Data" 52 "Pilot No Speed Data" 53 "Pilot Seatalk Fail1" 54 "Pilot Seatalk Fail2" 55 "Pilot Warning Too Fast To Fish" 56 "Pilot Auto Dockside Fail" 57 "Pilot Turn Too Fast" 58 "Pilot No Nav Data" 59 "Pilot Lost Waypoint Data" 60 "Pilot EEPROM Corrupt" 61 "Pilot Rudder Feedback Fail" 62 "Pilot Autolearn Fail1" 63 "Pilot Autolearn Fail2" 64 "Pilot Autolearn Fail3" 65 "Pilot Autolearn Fail4" 66 "Pilot Autolearn Fail5" 67 "Pilot Autolearn Fail6" 68 "Pilot Warning Cal Required" 69 "Pilot Warning OffCourse" 70 "Pilot Warning XTE" 71 "Pilot Warning Wind Shift" 72 "Pilot Warning Drive Short" 73 "Pilot Warning Clutch Short" 74 "Pilot Warning Solenoid Short" 75 "Pilot Joystick Fault" 76 "Pilot No Joystick Data" 80 "Pilot Invalid Command" 81 "AIS TX Malfunction" 82 "AIS Antenna VSWR fault" 83 "AIS Rx channel 1 malfunction" 84 "AIS Rx channel 2 malfunction" 85 "AIS No sensor position in use" 86 "AIS No valid SOG information" 87 "AIS No valid COG information" 88 "AIS 12V alarm" 89 "AIS 6V alarm" 90 "AIS Noise threshold exceeded channel A" 91 "AIS Noise threshold exceeded channel B" 92 "AIS Transmitter PA fault" 93 "AIS 3V3 alarm" 94 "AIS Rx channel 70 malfunction" 95 "AIS Heading lost/invalid" 96 "AIS internal GPS lost" 97 "AIS No sensor position" 98 "AIS Lock failure" 99 "AIS Internal GGA timeout" 100 "AIS Protocol stack restart" 101 "Pilot No IPS communications" 102 "Pilot Power-On or Sleep-Switch Reset While Engaged" 103 "Pilot Unexpected Reset While Engaged" 104 "AIS Dangerous Target" 105 "AIS Lost Target" 106 "AIS Safety Related Message (used to silence)" 107 "AIS Connection Lost" 108 "No Fix" ;
VAL_ 2566874110 pilotMode 0 "Standby" 64 "Auto, compass commanded" 256 "Vane, Wind Mode" 384 "Track Mode" 385 "No Drift, COG referenced (In track, course changes)" ;
VAL_ 2566881534 depthQualityFactor 0 "Depth unlocked" 1 "Quality 10%" 2 "Quality 20%" 3 "Quality 30%" 4 "Quality 40%" 5 "Quality 50%" 6 "Quality 60%" 7 "Quality 70%" 8 "Quality 80%" 9 "Quality 90%" 10 "Quality 100%" ;
VAL_ 2582647038 source 0 "GPS" 1 "GLONASS" 2 "Radio Station" 3 "Local Cesium clock" 4 "Local Rubidium clock" 5 "Local Crystal clock" ;
VAL_ 2582647294 equipmentStatus 0 "Operational" 1 "Fault" ;
VAL_ 2582647294 controller2State 0 "Error Active" 1 "Error Passive" 2 "Bus Off" ;
VAL_ 2582647294 controller1State 0 "Error Active" 1 "Error Passive" 2 "Bus Off" ;
VAL_ 2582711806 directionOrder 0 "No Order" 1 "Move to starboard" 2 "Move to port" ;
VAL_ 2582713086 reference 0 "True" 1 "Magnetic" 2 "Error" ;
VAL_ 2582715134 source 0 "Manual" 1 "Automatic Chart" 2 "Automatic Table" 3 "Automatic Calculation" 4 "WMM 2000" 5 "WMM 2005" 6 "WMM 2010" 7 "WMM 2015" 8 "WMM 2020" ;
VAL_ 2582774014 instance 0 "Single Engine or Dual Engine Port" 1 "Dual Engine Starboard" ;
VAL_ 2582775294 transmissionGear 0 "Forward" 1 "Neutral" 2 "Reverse" ;
VAL_ 2582775294 instance 0 "Single Engine or Dual Engine Port" 1 "Dual Engine Starboard" ;
VAL_ 2582777342 indicator28 0 "Off" 1 "On" ;
VAL_ 2582777342 indicator27 0 "Off" 1 "On" ;
VAL_ 2582777342 indicator26 0 "Off" 1 "On" ;
VAL_ 2582777342 indicator25 0 "Off" 1 "On" ;
VAL_ 2582777342 indicator24 0 "Off" 1 "On" ;
VAL_ 2582777342 indicator23 0 "Off" 1 "On" ;
VAL_ 2582777342 indicator22 0 "Off" 1 "On" ;
VAL_ 2582777342 indicator21 0 "Off" 1 "On" ;
VAL_ 2582777342 indicator20 0 "Off" 1 "On" ;
VAL_ 2582777342 indicator19 0 "Off" 1 "On" ;
VAL_ 2582777342 indicator18 0 "Off" 1 "On" ;
VAL_ 2582777342 indicator17 0 "Off" 1 "On" ;
VAL_ 2582777342 indicator16 0 "Off" 1 "On" ;
VAL_ 2582777342 indicator15 0 "Off" 1 "On" ;
VAL_ 2582777342 indicator14 0 "Off" 1 "On" ;
VAL_ 2582777342 indicator13 0 "Off" 1 "On" ;
VAL_ 2582777342 indicator12 0 "Off" 1 "On" ;
VAL_ 2582777342 indicator11 0 "Off" 1 "On" ;
VAL_ 2582777342 indicator10 0 "Off" 1 "On" ;
VAL_ 2582777342 indicator9 0 "Off" 1 "On" ;
VAL_ 2582777342 indicator8 0 "Off" 1 "On" ;
VAL_ 2582777342 indicator7 0 "Off" 1 "On" ;
VAL_ 2582777342 indicator6 0 "Off" 1 "On" ;
VAL_ 2582777342 indicator5 0 "Off" 1 "On" ;
VAL_ 2582777342 indicator4 0 "Off" 1 "On" ;
VAL_ 2582777342 indicator3 0 "Off" 1 "On" ;
VAL_ 2582777342 indicator2 0 "Off" 1 "On" ;
VAL_ 2582777342 indicator1 0 "Off" 1 "On" ;
VAL_ 2582777598 switch28 0 "Off" 1 "On" 2 "Reserved" 3 "Take no action (no change)" ;
VAL_ 2582777598 switch27 0 "Off" 1 "On" 2 "Reserved" 3 "Take no action (no change)" ;
VAL_ 2582777598 switch26 0 "Off" 1 "On" 2 "Reserved" 3 "Take no action (no change)" ;
VAL_ 2582777598 switch25 0 "Off" 1 "On" 2 "Reserved" 3 "Take no action (no change)" ;
VAL_ 2582777598 switch24 0 "Off" 1 "On" 2 "Reserved" 3 "Take no action (no change)" ;
VAL_ 2582777598 switch23 0 "Off" 1 "On" 2 "Reserved" 3 "Take no action (no change)" ;
VAL_ 2582777598 switch22 0 "Off" 1 "On" 2 "Reserved" 3 "Take no action (no change)" ;
VAL_ 2582777598 switch21 0 "Off" 1 "On" 2 "Reserved" 3 "Take no action (no change)" ;
VAL_ 2582777598 switch20 0 "Off" 1 "On" 2 "Reserved" 3 "Take no action (no change)" ;
VAL_ 2582777598 switch19 0 "Off" 1 "On" 2 "Reserved" 3 "Take no action (no change)" ;
VAL_ 2582777598 switch18 0 "Off" 1 "On" 2 "Reserved" 3 "Take no action (no change)" ;
VAL_ 2582777598 switch17 0 "Off" 1 "On" 2 "Reserved" 3 "Take no action (no change)" ;
VAL_ 2582777598 switch16 0 "Off" 1 "On" 2 "Reserved" 3 "Take no action (no change)" ;
VAL_ 2582777598 switch15 0 "Off" 1 "On" 2 "Reserved" 3 "Take no action (no change)" ;
VAL_ 2582777598 switch14 0 "Off" 1 "On" 2 "Reserved" 3 "Take no action (no change)" ;
VAL_ 2582777598 switch13 0 "Off" 1 "On" 2 "Reserved" 3 "Take no action (no change)" ;
VAL_ 2582777598 switch12 0 "Off" 1 "On" 2 "Reserved" 3 "Take no action (no change)" ;
VAL_ 2582777598 switch11 0 "Off" 1 "On" 2 "Reserved" 3 "Take no action (no change)" ;
VAL_ 2582777598 switch10 0 "Off" 1 "On" 2 "Reserved" 3 "Take no action (no change)" ;
VAL_ 2582777598 switch9 0 "Off" 1 "On" 2 "Reserved" 3 "Take no action (no change)" ;
VAL_ 2582777598 switch8 0 "Off" 1 "On" 2 "Reserved" 3 "Take no action (no change)" ;
VAL_ 2582777598 switch7 0 "Off" 1 "On" 2 "Reserved" 3 "Take no action (no change)" ;
VAL_ 2582777598 switch6 0 "Off" 1 "On" 2 "Reserved" 3 "Take no action (no change)" ;
VAL_ 2582777598 switch5 0 "Off" 1 "On" 2 "Reserved" 3 "Take no action (no change)" ;
VAL_ 2582777598 switch4 0 "Off" 1 "On" 2 "Reserved" 3 "Take no action (no change)" ;
VAL_ 2582777598 switch3 0 "Off" 1 "On" 2 "Reserved" 3 "Take no action (no change)" ;
VAL_ 2582777598 switch2 0 "Off" 1 "On" 2 "Reserved" 3 "Take no action (no change)" ;
VAL_ 2582777598 switch1 0 "Off" 1 "On" 2 "Reserved" 3 "Take no action (no change)" ;
VAL_ 2582778366 type 0 "Fuel" 1 "Water" 2 "Gray water" 3 "Live well" 4 "Oil" 5 "Black water" ;
VAL_ 2582841086 rippleState 0 "Good" 1 "Warning" 2 "Error" ;
VAL_ 2582841086 lowDcVoltageState 0 "Good" 1 "Warning" 2 "Error" ;
VAL_ 2582841086 overloadState 0 "Good" 1 "Warning" 2 "Error" ;
VAL_ 2582841086 temperatureState 0 "Good" 1 "Warning" 2 "Error" ;
VAL_ 2582841086 operatingState 0 "Off" 1 "Low Power Mode" 2 "Fault" 3 "Bulk" 4 "Absorption" 5 "Float" 6 "Storage" 7 "Equalize" 8 "Pass thru" 9 "Inverting" 10 "Assisting" ;
VAL_ 2582906622 retractControl 0 "Off" 1 "Extend" 2 "Retract" ;
VAL_ 2582906622 powerEnabled 0 "Off" 1 "On" ;
VAL_ 2582906622 directionControl 0 "Off" 1 "Ready" 2 "To Port" 3 "To Starboard" ;
VAL_ 2582906878 motorType 0 "12VDC" 1 "24VDC" 2 "48VDC" 3 "24VAC" 4 "Hydraulic" ;
VAL_ 2582971390 speedWaterReferencedType 0 "Paddle wheel" 1 "Pitot tube" 2 "Doppler" 3 "Correlation (ultra sound)" 4 "Electro Magnetic" ;
VAL_ 2583103742 anchorLight 0 "Off" 1 "On" ;
VAL_ 2583103742 deckAndAnchorWash 0 "Off" 1 "On" ;
VAL_ 2583103742 mechanicalLock 0 "Off" 1 "On" ;
VAL_ 2583103742 powerEnable 0 "Off" 1 "On" ;
VAL_ 2583103742 speedControlType 0 "Single speed" 1 "Dual speed" 2 "Proportional speed" ;
VAL_ 2583103742 anchorDockingControl 0 "Off" 1 "On" ;
VAL_ 2583103742 windlassDirectionControl 0 "Off" 1 "Down" 2 "Up" ;
VAL_ 2583103998 anchorDockingStatus 0 "Not docked" 1 "Fully docked" ;
VAL_ 2583103998 rodeTypeStatus 0 "Chain presently detected" 1 "Rope presently detected" ;
VAL_ 2583103998 windlassMotionStatus 0 "Windlass stopped" 1 "Deployment occurring" 2 "Retrieval occurring" ;
VAL_ 2583103998 windlassDirectionControl 0 "Off" 1 "Down" 2 "Up" ;
VAL_ 2583167742 cogReference 0 "True" 1 "Magnetic" 2 "Error" ;
VAL_ 2583168254 direction 0 "True" 1 "Magnetic" 2 "Error" ;
VAL_ 2583168254 gnssQuality 0 "no GNSS" 1 "GNSS fix" 2 "DGNSS fix" 3 "Precise GNSS" 4 "RTK Fixed Integer" 5 "RTK float" 6 "Estimated (DR) mode" 7 "Manual Input" 8 "Simulate mode" ;
VAL_ 2583233534 navigationTerminated 0 "No" 1 "Yes" ;
VAL_ 2583233534 xteMode 0 "Autonomous" 1 "Differential enhanced" 2 "Estimated" 3 "Simulator" 4 "Manual" ;
VAL_ 2583235582 setReference 0 "True" 1 "Magnetic" 2 "Error" ;
VAL_ 2583299070 actualMode 0 "1D" 1 "2D" 2 "3D" 3 "Auto" ;
VAL_ 2583299070 desiredMode 0 "1D" 1 "2D" 2 "3D" 3 "Auto" ;
VAL_ 2583301886 differentialOperationMode 0 "Manual" 1 "Auto Power" 2 "Auto Range" ;
VAL_ 2583301886 differentialSource 0 "Auto" 1 "Loran" 2 "MSK Beacon" 3 "FM Subcarrier" 4 "AIS" 5 "Ground based radio" 6 "SBAS" 7 "Satellite" ;
VAL_ 2583301886 serialInterfaceDetectionMode 0 "Auto bit rate" 1 "Manual bit rate" ;
VAL_ 2583301886 serialInterfaceBitRate 0 "25" 1 "50" 2 "100" 3 "200" 4 "300" 5 "600" 6 "1200" 7 "2400" 8 "4800" 9 "9600" 10 "19200" 11 "19200" 12 "38400" 13 "57600" ;
VAL_ 2583495422 reference 0 "True (ground referenced to North)" 1 "Magnetic (ground referenced to Magnetic North)" 2 "Apparent" 3 "True (boat referenced)" 4 "True (water referenced)" ;
VAL_ 2583496702 humiditySource 0 "Inside" 1 "Outside" ;
VAL_ 2583496702 temperatureSource 0 "Sea Temperature" 1 "Outside Temperature" 2 "Inside Temperature" 3 "Engine Room Temperature" 4 "Main Cabin Temperature" 5 "Live Well Temperature" 6 "Bait Well Temperature" 7 "Refrigeration Temperature" 8 "Heating System Temperature" 9 "Dew Point Temperature" 10 "Apparent Wind Chill Temperature" 11 "Theoretical Wind Chill Temperature" 12 "Heat Index Temperature" 13 "Freezer Temperature" 14 "Exhaust Gas Temperature" 15 "Shaft Seal Temperature" ;
VAL_ 2583496958 source 0 "Sea Temperature" 1 "Outside Temperature" 2 "Inside Temperature" 3 "Engine Room Temperature" 4 "Main Cabin Temperature" 5 "Live Well Temperature" 6 "Bait Well Temperature" 7 "Refrigeration Temperature" 8 "Heating System Temperature" 9 "Dew Point Temperature" 10 "Apparent Wind Chill Temperature" 11 "Theoretical Wind Chill Temperature" 12 "Heat Index Temperature" 13 "Freezer Temperature" 14 "Exhaust Gas Temperature" 15 "Shaft Seal Temperature" ;
VAL_ 2583497214 source 0 "Inside" 1 "Outside" ;
VAL_ 2583497470 source 0 "Atmospheric" 1 "Water" 2 "Steam" 3 "Compressed Air" 4 "Hydraulic" 5 "Filter" 6 "AltimeterSetting" 7 "Oil" 8 "Fuel" ;
VAL_ 2583497726 source 0 "Atmospheric" 1 "Water" 2 "Steam" 3 "Compressed Air" 4 "Hydraulic" 5 "Filter" 6 "AltimeterSetting" 7 "Oil" 8 "Fuel" ;
VAL_ 2583497982 source 0 "Sea Temperature" 1 "Outside Temperature" 2 "Inside Temperature" 3 "Engine Room Temperature" 4 "Main Cabin Temperature" 5 "Live Well Temperature" 6 "Bait Well Temperature" 7 "Refrigeration Temperature" 8 "Heating System Temperature" 9 "Dew Point Temperature" 10 "Apparent Wind Chill Temperature" 11 "Theoretical Wind Chill Temperature" 12 "Heat Index Temperature" 13 "Freezer Temperature" 14 "Exhaust Gas Temperature" 15 "Shaft Seal Temperature" ;
VAL_ 2583565310 videoProtocols 0 "PAL" 1 "NTSC" ;
VAL_ 2583565310 tunerRegions 0 "USA" 1 "Europe" 2 "Asia" 3 "Middle East" 4 "Latin America" 5 "Australia" 6 "Russia" 7 "Japan" ;
VAL_ 2583565310 defaultSettings 0 "Save current settings as user default" 1 "Load user default" 2 "Load manufacturer default" ;
VAL_ 2583565310 power 0 "No" 1 "Yes" ;
VAL_ 2583566078 channel 0 "All channels" 1 "Stereo full range" 2 "Stereo front" 3 "Stereo back" 4 "Stereo surround" 5 "Center" 6 "Subwoofer" 7 "Front left" 8 "Front right" 9 "Back left" 10 "Back right" 11 "Surround left" 12 "Surround right" ;
VAL_ 2583566078 mute 0 "No" 1 "Yes" ;
VAL_ 2583566078 volumeChange 0 "Up" 1 "Down" ;
VAL_ 2583566078 zoneId 0 "All zones" 1 "Zone 1" 2 "Zone 2" 3 "Zone 3" 4 "Zone 4" ;
VAL_ 2583566846 discovering 0 "No" 1 "Yes" ;
VAL_ 2583566846 forgetDevice 0 "No" 1 "Yes" ;
VAL_ 2583566846 status 0 "Reserved" 1 "Connected" 2 "Connecting" 3 "Not connected" ;
